AUTOSAR XML (schema 4-2-2)
package /STELLANTIS/EPT/ASWCs
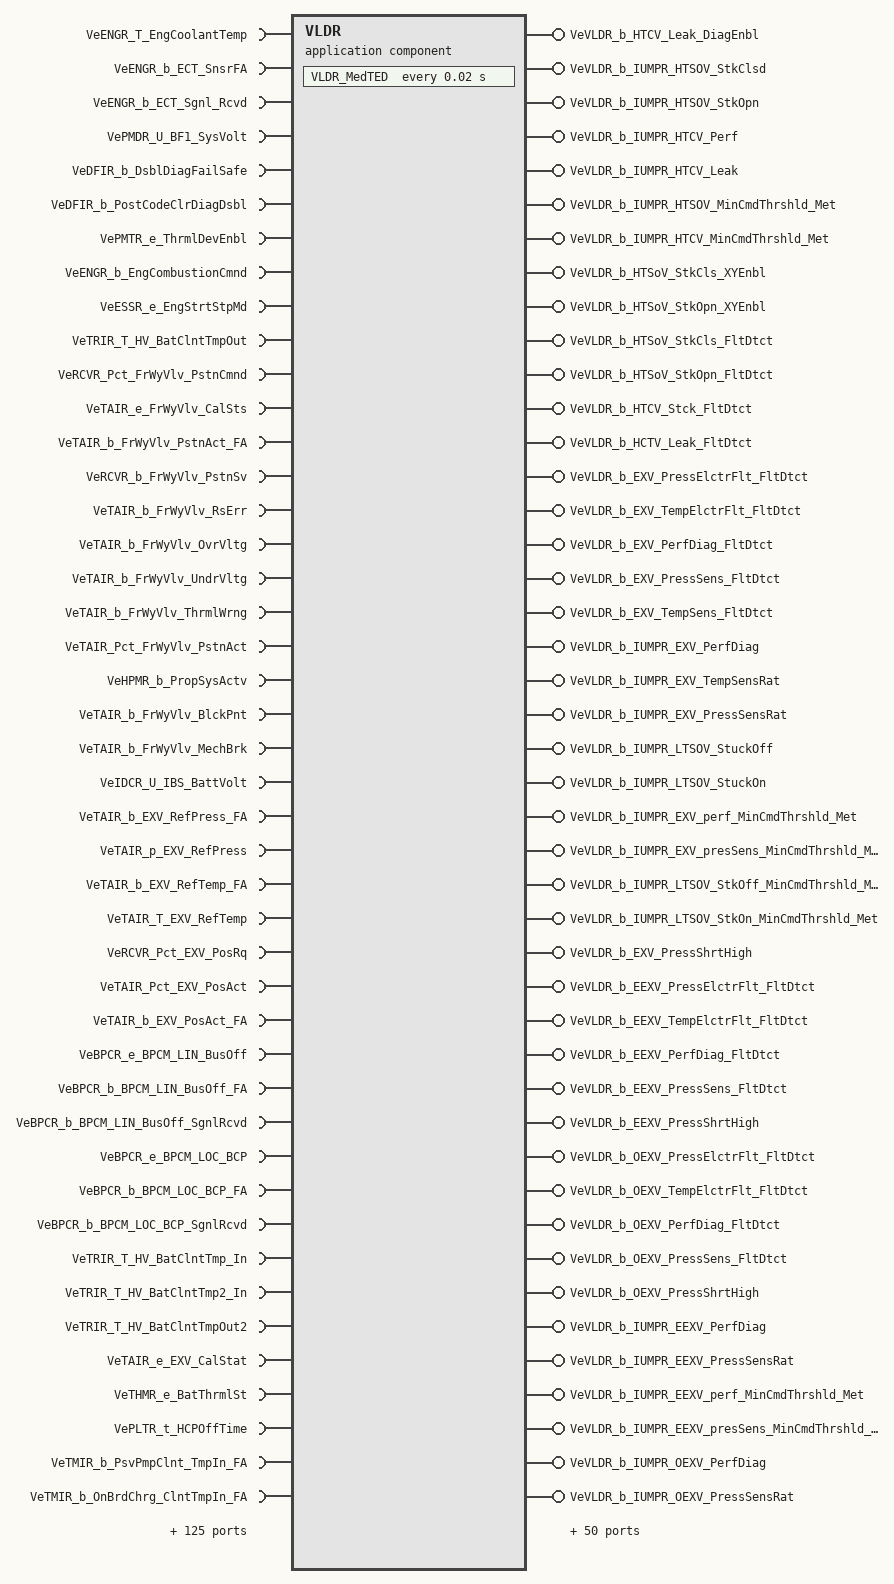
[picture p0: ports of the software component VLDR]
  application sw component type VLDR
    145 x require port:
      VeENGR_T_EngCoolantTemp: variation-point={short-label=vpVeENGR_T_EngCoolantTemp, sw-syscond=1}, nonqueued-receiver-com-spec{data-element=Value, init-value=0}, required-interface=VeENGR_T_EngCoolantTemp
      VeENGR_b_ECT_SnsrFA: variation-point={short-label=vpVeENGR_b_ECT_SnsrFA, sw-syscond=1}, nonqueued-receiver-com-spec{data-element=Value, init-value=0}, required-interface=VeENGR_b_ECT_SnsrFA
      VeENGR_b_ECT_Sgnl_Rcvd: variation-point={short-label=vpVeENGR_b_ECT_Sgnl_Rcvd, sw-syscond=1}, nonqueued-receiver-com-spec{data-element=Value, init-value=0}, required-interface=VeENGR_b_ECT_Sgnl_Rcvd
      VePMDR_U_BF1_SysVolt: variation-point={short-label=vpVePMDR_U_BF1_SysVolt, sw-syscond=1}, nonqueued-receiver-com-spec{data-element=Value, init-value=0}, required-interface=VePMDR_U_BF1_SysVolt
      VeDFIR_b_DsblDiagFailSafe: variation-point={short-label=vpVeDFIR_b_DsblDiagFailSafe, sw-syscond=1}, nonqueued-receiver-com-spec{data-element=Value, init-value=0}, required-interface=VeDFIR_b_DsblDiagFailSafe
      VeDFIR_b_PostCodeClrDiagDsbl: variation-point={short-label=vpVeDFIR_b_PostCodeClrDiagDsbl, sw-syscond=1}, nonqueued-receiver-com-spec{data-element=Value, init-value=0}, required-interface=VeDFIR_b_PostCodeClrDiagDsbl
      VePMTR_e_ThrmlDevEnbl: variation-point={short-label=vpVePMTR_e_ThrmlDevEnbl, sw-syscond=1}, nonqueued-receiver-com-spec{data-element=Value, init-value=CePMTR_e_DISBL_All_Thrml}, required-interface=VePMTR_e_ThrmlDevEnbl
      VeENGR_b_EngCombustionCmnd: variation-point={short-label=vpVeENGR_b_EngCombustionCmnd, sw-syscond=1}, nonqueued-receiver-com-spec{data-element=Value, init-value=0}, required-interface=VeENGR_b_EngCombustionCmnd
      VeESSR_e_EngStrtStpMd: variation-point={short-label=vpVeESSR_e_EngStrtStpMd, sw-syscond=1}, nonqueued-receiver-com-spec{data-element=Value, init-value=CeESSR_e_Stop}, required-interface=VeESSR_e_EngStrtStpMd
      VeTRIR_T_HV_BatClntTmpOut: variation-point={short-label=vpVeTRIR_T_HV_BatClntTmpOut, sw-syscond=1}, nonqueued-receiver-com-spec{data-element=Value, init-value=0}, required-interface=VeTRIR_T_HV_BatClntTmpOut
      VeRCVR_Pct_FrWyVlv_PstnCmnd: variation-point={short-label=vpVeRCVR_Pct_FrWyVlv_PstnCmnd, sw-syscond=1}, nonqueued-receiver-com-spec{data-element=Value, init-value=0}, required-interface=VeRCVR_Pct_FrWyVlv_PstnCmnd
      VeTAIR_e_FrWyVlv_CalSts: variation-point={short-label=vpVeTAIR_e_FrWyVlv_CalSts, sw-syscond=1}, nonqueued-receiver-com-spec{data-element=Value, init-value=CeTAIR_e_CPV_Calibration_Complete}, required-interface=VeTAIR_e_FrWyVlv_CalSts
      VeTAIR_b_FrWyVlv_PstnAct_FA: variation-point={short-label=vpVeTAIR_b_FrWyVlv_PstnAct_FA, sw-syscond=1}, nonqueued-receiver-com-spec{data-element=Value, init-value=0}, required-interface=VeTAIR_b_FrWyVlv_PstnAct_FA
      VeRCVR_b_FrWyVlv_PstnSv: variation-point={short-label=vpVeRCVR_b_FrWyVlv_PstnSv, sw-syscond=1}, nonqueued-receiver-com-spec{data-element=Value, init-value=0}, required-interface=VeRCVR_b_FrWyVlv_PstnSv
      VeTAIR_b_FrWyVlv_RsErr: variation-point={short-label=vpVeTAIR_b_FrWyVlv_RsErr, sw-syscond=1}, nonqueued-receiver-com-spec{data-element=Value, init-value=0}, required-interface=VeTAIR_b_FrWyVlv_RsErr
      VeTAIR_b_FrWyVlv_OvrVltg: variation-point={short-label=vpVeTAIR_b_FrWyVlv_OvrVltg, sw-syscond=1}, nonqueued-receiver-com-spec{data-element=Value, init-value=0}, required-interface=VeTAIR_b_FrWyVlv_OvrVltg
      VeTAIR_b_FrWyVlv_UndrVltg: variation-point={short-label=vpVeTAIR_b_FrWyVlv_UndrVltg, sw-syscond=1}, nonqueued-receiver-com-spec{data-element=Value, init-value=0}, required-interface=VeTAIR_b_FrWyVlv_UndrVltg
      VeTAIR_b_FrWyVlv_ThrmlWrng: variation-point={short-label=vpVeTAIR_b_FrWyVlv_ThrmlWrng, sw-syscond=1}, nonqueued-receiver-com-spec{data-element=Value, init-value=0}, required-interface=VeTAIR_b_FrWyVlv_ThrmlWrng
      VeTAIR_Pct_FrWyVlv_PstnAct: variation-point={short-label=vpVeTAIR_Pct_FrWyVlv_PstnAct, sw-syscond=1}, nonqueued-receiver-com-spec{data-element=Value, init-value=0}, required-interface=VeTAIR_Pct_FrWyVlv_PstnAct
      VeHPMR_b_PropSysActv: variation-point={short-label=vpVeHPMR_b_PropSysActv, sw-syscond=1}, nonqueued-receiver-com-spec{data-element=Value, init-value=0}, required-interface=VeHPMR_b_PropSysActv
      VeTAIR_b_FrWyVlv_BlckPnt: variation-point={short-label=vpVeTAIR_b_FrWyVlv_BlckPnt, sw-syscond=1}, nonqueued-receiver-com-spec{data-element=Value, init-value=0}, required-interface=VeTAIR_b_FrWyVlv_BlckPnt
      VeTAIR_b_FrWyVlv_MechBrk: variation-point={short-label=vpVeTAIR_b_FrWyVlv_MechBrk, sw-syscond=1}, nonqueued-receiver-com-spec{data-element=Value, init-value=0}, required-interface=VeTAIR_b_FrWyVlv_MechBrk
      VeIDCR_U_IBS_BattVolt: variation-point={short-label=vpVeIDCR_U_IBS_BattVolt, sw-syscond=1}, nonqueued-receiver-com-spec{data-element=Value, init-value=0}, required-interface=VeIDCR_U_IBS_BattVolt
      VeTAIR_b_EXV_RefPress_FA: variation-point={short-label=vpVeTAIR_b_EXV_RefPress_FA, sw-syscond=1}, nonqueued-receiver-com-spec{data-element=Value, init-value=0}, required-interface=VeTAIR_b_EXV_RefPress_FA
      VeTAIR_p_EXV_RefPress: variation-point={short-label=vpVeTAIR_p_EXV_RefPress, sw-syscond=1}, nonqueued-receiver-com-spec{data-element=Value, init-value=0}, required-interface=VeTAIR_p_EXV_RefPress
      VeTAIR_b_EXV_RefTemp_FA: variation-point={short-label=vpVeTAIR_b_EXV_RefTemp_FA, sw-syscond=1}, nonqueued-receiver-com-spec{data-element=Value, init-value=0}, required-interface=VeTAIR_b_EXV_RefTemp_FA
      VeTAIR_T_EXV_RefTemp: variation-point={short-label=vpVeTAIR_T_EXV_RefTemp, sw-syscond=1}, nonqueued-receiver-com-spec{data-element=Value, init-value=0}, required-interface=VeTAIR_T_EXV_RefTemp
      VeRCVR_Pct_EXV_PosRq: variation-point={short-label=vpVeRCVR_Pct_EXV_PosRq, sw-syscond=1}, nonqueued-receiver-com-spec{data-element=Value, init-value=0}, required-interface=VeRCVR_Pct_EXV_PosRq
      VeTAIR_Pct_EXV_PosAct: variation-point={short-label=vpVeTAIR_Pct_EXV_PosAct, sw-syscond=1}, nonqueued-receiver-com-spec{data-element=Value, init-value=0}, required-interface=VeTAIR_Pct_EXV_PosAct
      VeTAIR_b_EXV_PosAct_FA: variation-point={short-label=vpVeTAIR_b_EXV_PosAct_FA, sw-syscond=1}, nonqueued-receiver-com-spec{data-element=Value, init-value=0}, required-interface=VeTAIR_b_EXV_PosAct_FA
      VeBPCR_e_BPCM_LIN_BusOff: variation-point={short-label=vpVeBPCR_e_BPCM_LIN_BusOff, sw-syscond=1}, nonqueued-receiver-com-spec{data-element=Value, init-value=CeBPCR_e_LIN_BusOff_Disabled}, required-interface=VeBPCR_e_BPCM_LIN_BusOff
      VeBPCR_b_BPCM_LIN_BusOff_FA: variation-point={short-label=vpVeBPCR_b_BPCM_LIN_BusOff_FA, sw-syscond=1}, nonqueued-receiver-com-spec{data-element=Value, init-value=0}, required-interface=VeBPCR_b_BPCM_LIN_BusOff_FA
      VeBPCR_b_BPCM_LIN_BusOff_SgnlRcvd: variation-point={short-label=vpVeBPCR_b_BPCM_LIN_BusOff_SgnlRcvd, sw-syscond=1}, nonqueued-receiver-com-spec{data-element=Value, init-value=0}, required-interface=VeBPCR_b_BPCM_LIN_BusOff_SgnlRcvd
      VeBPCR_e_BPCM_LOC_BCP: variation-point={short-label=vpVeBPCR_e_BPCM_LOC_BCP, sw-syscond=1}, nonqueued-receiver-com-spec{data-element=Value, init-value=CeBPCR_e_LOC_BCP_False}, required-interface=VeBPCR_e_BPCM_LOC_BCP
      VeBPCR_b_BPCM_LOC_BCP_FA: variation-point={short-label=vpVeBPCR_b_BPCM_LOC_BCP_FA, sw-syscond=1}, nonqueued-receiver-com-spec{data-element=Value, init-value=0}, required-interface=VeBPCR_b_BPCM_LOC_BCP_FA
      VeBPCR_b_BPCM_LOC_BCP_SgnlRcvd: variation-point={short-label=vpVeBPCR_b_BPCM_LOC_BCP_SgnlRcvd, sw-syscond=1}, nonqueued-receiver-com-spec{data-element=Value, init-value=0}, required-interface=VeBPCR_b_BPCM_LOC_BCP_SgnlRcvd
      VeTRIR_T_HV_BatClntTmp_In: variation-point={short-label=vpVeTRIR_T_HV_BatClntTmp_In, sw-syscond=1}, nonqueued-receiver-com-spec{data-element=Value, init-value=0}, required-interface=VeTRIR_T_HV_BatClntTmp_In
      VeTRIR_T_HV_BatClntTmp2_In: variation-point={short-label=vpVeTRIR_T_HV_BatClntTmp2_In, sw-syscond=1}, nonqueued-receiver-com-spec{data-element=Value, init-value=0}, required-interface=VeTRIR_T_HV_BatClntTmp2_In
      VeTRIR_T_HV_BatClntTmpOut2: variation-point={short-label=vpVeTRIR_T_HV_BatClntTmpOut2, sw-syscond=1}, nonqueued-receiver-com-spec{data-element=Value, init-value=0}, required-interface=VeTRIR_T_HV_BatClntTmpOut2
      VeTAIR_e_EXV_CalStat: variation-point={short-label=vpVeTAIR_e_EXV_CalStat, sw-syscond=1}, nonqueued-receiver-com-spec{data-element=Value, init-value=CeTAIR_e_EXV_Calibration_Complete}, required-interface=VeTAIR_e_EXV_CalStat
      VeTHMR_e_BatThrmlSt: variation-point={short-label=vpVeTHMR_e_BatThrmlSt, sw-syscond=1}, nonqueued-receiver-com-spec{data-element=Value, init-value=CeTHMR_e_NoConditioning}, required-interface=VeTHMR_e_BatThrmlSt
      VePLTR_t_HCPOffTime: variation-point={short-label=vpVePLTR_t_HCPOffTime, sw-syscond=1}, nonqueued-receiver-com-spec{data-element=Value, init-value=0}, required-interface=VePLTR_t_HCPOffTime
      VeTMIR_b_PsvPmpClnt_TmpIn_FA: variation-point={short-label=vpVeTMIR_b_PsvPmpClnt_TmpIn_FA, sw-syscond=1}, nonqueued-receiver-com-spec{data-element=Value, init-value=0}, required-interface=VeTMIR_b_PsvPmpClnt_TmpIn_FA
      VeTMIR_b_OnBrdChrg_ClntTmpIn_FA: variation-point={short-label=vpVeTMIR_b_OnBrdChrg_ClntTmpIn_FA, sw-syscond=1}, nonqueued-receiver-com-spec{data-element=Value, init-value=0}, required-interface=VeTMIR_b_OnBrdChrg_ClntTmpIn_FA
      VeRCVR_Pct_LTR_Vlv_PstnCmnd: variation-point={short-label=vpVeRCVR_Pct_LTR_Vlv_PstnCmnd, sw-syscond=1}, nonqueued-receiver-com-spec{data-element=Value, init-value=0}, required-interface=VeRCVR_Pct_LTR_Vlv_PstnCmnd
      VeTAIR_Pct_LTR_BypsVlv_ActlPstn: variation-point={short-label=vpVeTAIR_Pct_LTR_BypsVlv_ActlPstn, sw-syscond=1}, nonqueued-receiver-com-spec{data-element=Value, init-value=0}, required-interface=VeTAIR_Pct_LTR_BypsVlv_ActlPstn
      VeTAIR_b_LTR_BypsVlv_ActlPstn_FA: variation-point={short-label=vpVeTAIR_b_LTR_BypsVlv_ActlPstn_FA, sw-syscond=1}, nonqueued-receiver-com-spec{data-element=Value, init-value=0}, required-interface=VeTAIR_b_LTR_BypsVlv_ActlPstn_FA
      VeRCVR_Pct_HTL_Vlv_PstnCmnd: variation-point={short-label=vpVeRCVR_Pct_HTL_Vlv_PstnCmnd, sw-syscond=1}, nonqueued-receiver-com-spec{data-element=Value, init-value=0}, required-interface=VeRCVR_Pct_HTL_Vlv_PstnCmnd
      VeTAIR_Pct_HTL_BypsVlv_ActlPstn: variation-point={short-label=vpVeTAIR_Pct_HTL_BypsVlv_ActlPstn, sw-syscond=1}, nonqueued-receiver-com-spec{data-element=Value, init-value=0}, required-interface=VeTAIR_Pct_HTL_BypsVlv_ActlPstn
      VeTAIR_b_HTL_BypsVlv_ActlPstn_FA: variation-point={short-label=vpVeTAIR_b_HTL_BypsVlv_ActlPstn_FA, sw-syscond=1}, nonqueued-receiver-com-spec{data-element=Value, init-value=0}, required-interface=VeTAIR_b_HTL_BypsVlv_ActlPstn_FA
      VeDFIR_b_IsDiagGlobalConditionsValid: variation-point={short-label=vpVeDFIR_b_IsDiagGlobalConditionsValid, sw-syscond=1}, nonqueued-receiver-com-spec{data-element=Value, init-value=0}, required-interface=VeDFIR_b_IsDiagGlobalConditionsValid
      VeTAIR_n_CompSpdFdb: variation-point={short-label=vpVeTAIR_n_CompSpdFdb, sw-syscond=1}, nonqueued-receiver-com-spec{data-element=Value, init-value=0}, required-interface=VeTAIR_n_CompSpdFdb
      VeTMIR_b_MainRly_CmdReq: variation-point={short-label=vpVeTMIR_b_MainRly_CmdReq, sw-syscond=1}, nonqueued-receiver-com-spec{data-element=Value, init-value=0}, required-interface=VeTMIR_b_MainRly_CmdReq
      VeTAIR_p_OEXV_RefPress: variation-point={short-label=vpVeTAIR_p_OEXV_RefPress, sw-syscond=1}, nonqueued-receiver-com-spec{data-element=Value, init-value=0}, required-interface=VeTAIR_p_OEXV_RefPress
      VeTAIR_b_OEXV_RefPress_FA: variation-point={short-label=vpVeTAIR_b_OEXV_RefPress_FA, sw-syscond=1}, nonqueued-receiver-com-spec{data-element=Value, init-value=0}, required-interface=VeTAIR_b_OEXV_RefPress_FA
      VeTAIR_T_OEXV_RefTemp: variation-point={short-label=vpVeTAIR_T_OEXV_RefTemp, sw-syscond=1}, nonqueued-receiver-com-spec{data-element=Value, init-value=0}, required-interface=VeTAIR_T_OEXV_RefTemp
      VeRCVR_Pct_OEXV_Cmd: variation-point={short-label=vpVeRCVR_Pct_OEXV_Cmd, sw-syscond=1}, nonqueued-receiver-com-spec{data-element=Value, init-value=0}, required-interface=VeRCVR_Pct_OEXV_Cmd
      VeTAIR_Pct_OEXV_PosAct: variation-point={short-label=vpVeTAIR_Pct_OEXV_PosAct, sw-syscond=1}, nonqueued-receiver-com-spec{data-element=Value, init-value=0}, required-interface=VeTAIR_Pct_OEXV_PosAct
      VeTAIR_b_OEXV_PosAct_FA: variation-point={short-label=vpVeTAIR_b_OEXV_PosAct_FA, sw-syscond=1}, nonqueued-receiver-com-spec{data-element=Value, init-value=0}, required-interface=VeTAIR_b_OEXV_PosAct_FA
      VeTAIR_e_OEXV_CalStat: variation-point={short-label=vpVeTAIR_e_OEXV_CalStat, sw-syscond=1}, nonqueued-receiver-com-spec{data-element=Value, init-value=CeTAIR_e_EXV_Calibration_Complete}, required-interface=VeTAIR_e_OEXV_CalStat
      VeTAIR_e_CompStat: variation-point={short-label=vpVeTAIR_e_CompStat, sw-syscond=1}, nonqueued-receiver-com-spec{data-element=Value, init-value=CeTAIR_e_NormalOp}, required-interface=VeTAIR_e_CompStat
      VeTAIR_b_WinshldDfrst: variation-point={short-label=vpVeTAIR_b_WinshldDfrst, sw-syscond=1}, nonqueued-receiver-com-spec{data-element=Value, init-value=0}, required-interface=VeTAIR_b_WinshldDfrst
      VeTAIR_p_EEXV_RefPress: variation-point={short-label=vpVeTAIR_p_EEXV_RefPress, sw-syscond=1}, nonqueued-receiver-com-spec{data-element=Value, init-value=0}, required-interface=VeTAIR_p_EEXV_RefPress
      VeTAIR_b_EEXV_RefPress_FA: variation-point={short-label=vpVeTAIR_b_EEXV_RefPress_FA, sw-syscond=1}, nonqueued-receiver-com-spec{data-element=Value, init-value=0}, required-interface=VeTAIR_b_EEXV_RefPress_FA
      VeTAIR_T_EEXV_RefTemp: variation-point={short-label=vpVeTAIR_T_EEXV_RefTemp, sw-syscond=1}, nonqueued-receiver-com-spec{data-element=Value, init-value=0}, required-interface=VeTAIR_T_EEXV_RefTemp
      VeRCVR_Pct_EEXV_Cmd: variation-point={short-label=vpVeRCVR_Pct_EEXV_Cmd, sw-syscond=1}, nonqueued-receiver-com-spec{data-element=Value, init-value=0}, required-interface=VeRCVR_Pct_EEXV_Cmd
      VeTAIR_Pct_EEXV_PosAct: variation-point={short-label=vpVeTAIR_Pct_EEXV_PosAct, sw-syscond=1}, nonqueued-receiver-com-spec{data-element=Value, init-value=0}, required-interface=VeTAIR_Pct_EEXV_PosAct
      VeTAIR_b_EEXV_PosAct_FA: variation-point={short-label=vpVeTAIR_b_EEXV_PosAct_FA, sw-syscond=1}, nonqueued-receiver-com-spec{data-element=Value, init-value=0}, required-interface=VeTAIR_b_EEXV_PosAct_FA
      VeTAIR_e_EEXV_CalStat: variation-point={short-label=vpVeTAIR_e_EEXV_CalStat, sw-syscond=1}, nonqueued-receiver-com-spec{data-element=Value, init-value=CeTAIR_e_EXV_Calibration_Complete}, required-interface=VeTAIR_e_EEXV_CalStat
      VeDMAB_y_StatusByte_LIN1_BusOff: nonqueued-receiver-com-spec{data-element=Value, init-value=0}, required-interface=VeDMAB_y_StatusByte_LIN1_BusOff
      VeDMAB_y_StatusByte_LIN2_BusOff: nonqueued-receiver-com-spec{data-element=Value, init-value=0}, required-interface=VeDMAB_y_StatusByte_LIN2_BusOff
      VeDMAB_y_StatusByte_LosCommHybPSCCtrlValA: nonqueued-receiver-com-spec{data-element=Value, init-value=0}, required-interface=VeDMAB_y_StatusByte_LosCommHybPSCCtrlValA
      VeDMAB_y_StatusByte_ThrmlRlyCtrlCkt: nonqueued-receiver-com-spec{data-element=Value, init-value=0}, required-interface=VeDMAB_y_StatusByte_ThrmlRlyCtrlCkt
      VeDMAB_y_StatusByte_LostCommACRefrigExpVlvActC: nonqueued-receiver-com-spec{data-element=Value, init-value=0}, required-interface=VeDMAB_y_StatusByte_LostCommACRefrigExpVlvActC
      VeDMAB_y_StatusByte_AC_RefrigPresSnsrCCktPerf: nonqueued-receiver-com-spec{data-element=Value, init-value=0}, required-interface=VeDMAB_y_StatusByte_AC_RefrigPresSnsrCCktPerf
      VeDMAB_y_StatusByte_AC_RefrigExpVlvAct_C_CntrlCktPerf: nonqueued-receiver-com-spec{data-element=Value, init-value=0}, required-interface=VeDMAB_y_StatusByte_AC_RefrigExpVlvAct_C_CntrlCktPerf
      VeDMAB_y_StatusByte_AC_RefrigPresSnsrAHi: nonqueued-receiver-com-spec{data-element=Value, init-value=0}, required-interface=VeDMAB_y_StatusByte_AC_RefrigPresSnsrAHi
      VeDMAB_y_StatusByte_AC_RefrigPresSnsrALo: nonqueued-receiver-com-spec{data-element=Value, init-value=0}, required-interface=VeDMAB_y_StatusByte_AC_RefrigPresSnsrALo
      VeDMAB_y_StatusByte_AC_RefrigPresSnsrAPerf: nonqueued-receiver-com-spec{data-element=Value, init-value=0}, required-interface=VeDMAB_y_StatusByte_AC_RefrigPresSnsrAPerf
      VeDMAB_y_StatusByte_AC_RefrigPresSnsrCCkt: nonqueued-receiver-com-spec{data-element=Value, init-value=0}, required-interface=VeDMAB_y_StatusByte_AC_RefrigPresSnsrCCkt
      VeDMAB_y_StatusByte_AC_RefrigTempSnsrCCkt: nonqueued-receiver-com-spec{data-element=Value, init-value=0}, required-interface=VeDMAB_y_StatusByte_AC_RefrigTempSnsrCCkt
      VeDMAB_y_StatusByte_AC_RefrigTempSnsrCPerf: nonqueued-receiver-com-spec{data-element=Value, init-value=0}, required-interface=VeDMAB_y_StatusByte_AC_RefrigTempSnsrCPerf
      VeDMAB_y_StatusByte_EACPerf: nonqueued-receiver-com-spec{data-element=Value, init-value=0}, required-interface=VeDMAB_y_StatusByte_EACPerf
      VeDMAB_y_StatusByte_LostCommEAC: nonqueued-receiver-com-spec{data-element=Value, init-value=0}, required-interface=VeDMAB_y_StatusByte_LostCommEAC
      VeDMAB_y_StatusByte_CoolantVlvA_CktHi: nonqueued-receiver-com-spec{data-element=Value, init-value=0}, required-interface=VeDMAB_y_StatusByte_CoolantVlvA_CktHi
      VeDMAB_y_StatusByte_CoolantVlvA_CktLo: nonqueued-receiver-com-spec{data-element=Value, init-value=0}, required-interface=VeDMAB_y_StatusByte_CoolantVlvA_CktLo
      VeDMAB_y_StatusByte_CoolantVlvA_Ckt: nonqueued-receiver-com-spec{data-element=Value, init-value=0}, required-interface=VeDMAB_y_StatusByte_CoolantVlvA_Ckt
      VeDMAB_y_StatusByte_BattCoolPmpATempSnsrPerf: nonqueued-receiver-com-spec{data-element=Value, init-value=0}, required-interface=VeDMAB_y_StatusByte_BattCoolPmpATempSnsrPerf
      VeDMAB_y_StatusByte_CoolOutTempSnsCkt: nonqueued-receiver-com-spec{data-element=Value, init-value=0}, required-interface=VeDMAB_y_StatusByte_CoolOutTempSnsCkt
      VeDMAB_y_StatusByte_HB_CT_SnsrPerf: nonqueued-receiver-com-spec{data-element=Value, init-value=0}, required-interface=VeDMAB_y_StatusByte_HB_CT_SnsrPerf
      VeDMAB_y_StatusByte_CoolantVlvA_FdbkCktHi: nonqueued-receiver-com-spec{data-element=Value, init-value=0}, required-interface=VeDMAB_y_StatusByte_CoolantVlvA_FdbkCktHi
      VeDMAB_y_StatusByte_CoolantVlvA_FdbkCktLo: nonqueued-receiver-com-spec{data-element=Value, init-value=0}, required-interface=VeDMAB_y_StatusByte_CoolantVlvA_FdbkCktLo
      VeDMAB_y_StatusByte_LIN3_BusOff: nonqueued-receiver-com-spec{data-element=Value, init-value=0}, required-interface=VeDMAB_y_StatusByte_LIN3_BusOff
      VeDMAB_y_StatusByte_LostCommHB_PSCCooCtrlVlvC: nonqueued-receiver-com-spec{data-element=Value, init-value=0}, required-interface=VeDMAB_y_StatusByte_LostCommHB_PSCCooCtrlVlvC
      VeDMAB_y_StatusByte_CoolantVlvB_CktHi: nonqueued-receiver-com-spec{data-element=Value, init-value=0}, required-interface=VeDMAB_y_StatusByte_CoolantVlvB_CktHi
      VeDMAB_y_StatusByte_CoolantVlvB_CktLo: nonqueued-receiver-com-spec{data-element=Value, init-value=0}, required-interface=VeDMAB_y_StatusByte_CoolantVlvB_CktLo
      VeDMAB_y_StatusByte_CoolantVlvB_Ckt: nonqueued-receiver-com-spec{data-element=Value, init-value=0}, required-interface=VeDMAB_y_StatusByte_CoolantVlvB_Ckt
      VeDMAB_y_StatusByte_LostCommCoolHtrA: nonqueued-receiver-com-spec{data-element=Value, init-value=0}, required-interface=VeDMAB_y_StatusByte_LostCommCoolHtrA
      VeDMAB_y_StatusByte_CoolantVlvB_StkClsd: nonqueued-receiver-com-spec{data-element=Value, init-value=0}, required-interface=VeDMAB_y_StatusByte_CoolantVlvB_StkClsd
      VeDMAB_y_StatusByte_CoolantVlvB_StkOpn: nonqueued-receiver-com-spec{data-element=Value, init-value=0}, required-interface=VeDMAB_y_StatusByte_CoolantVlvB_StkOpn
      VeDMAB_y_StatusByte_CT_SnsrCktHi: nonqueued-receiver-com-spec{data-element=Value, init-value=0}, required-interface=VeDMAB_y_StatusByte_CT_SnsrCktHi
      VeDMAB_y_StatusByte_CT_SnsrCktLo: nonqueued-receiver-com-spec{data-element=Value, init-value=0}, required-interface=VeDMAB_y_StatusByte_CT_SnsrCktLo
      VeDMAB_y_StatusByte_CT_SnsrPerf: nonqueued-receiver-com-spec{data-element=Value, init-value=0}, required-interface=VeDMAB_y_StatusByte_CT_SnsrPerf
      VeDMAB_y_StatusByte_HybEvBatPacCoolCtrlVlvBStkOn: nonqueued-receiver-com-spec{data-element=Value, init-value=0}, required-interface=VeDMAB_y_StatusByte_HybEvBatPacCoolCtrlVlvBStkOn
      VeDMAB_y_StatusByte_LosCommBECM_A: nonqueued-receiver-com-spec{data-element=Value, init-value=0}, required-interface=VeDMAB_y_StatusByte_LosCommBECM_A
      VeDMAB_y_StatusByte_MtrElect_CT_SnsrCktHi: nonqueued-receiver-com-spec{data-element=Value, init-value=0}, required-interface=VeDMAB_y_StatusByte_MtrElect_CT_SnsrCktHi
      VeDMAB_y_StatusByte_MtrElect_CT_SnsrCktLo: nonqueued-receiver-com-spec{data-element=Value, init-value=0}, required-interface=VeDMAB_y_StatusByte_MtrElect_CT_SnsrCktLo
      VeDMAB_y_StatusByte_MtrElect_CT_SnsrPerf: nonqueued-receiver-com-spec{data-element=Value, init-value=0}, required-interface=VeDMAB_y_StatusByte_MtrElect_CT_SnsrPerf
      VeDMAB_y_StatusByte_HybEvBatPacCoolCtrlVlvBPerfStkOff: nonqueued-receiver-com-spec{data-element=Value, init-value=0}, required-interface=VeDMAB_y_StatusByte_HybEvBatPacCoolCtrlVlvBPerfStkOff
      VeDMAB_y_StatusByte_LostCommHB_PSCCooCtrlVlvB: nonqueued-receiver-com-spec{data-element=Value, init-value=0}, required-interface=VeDMAB_y_StatusByte_LostCommHB_PSCCooCtrlVlvB
      VeDMAB_y_StatusByte_CommBusOff: nonqueued-receiver-com-spec{data-element=Value, init-value=0}, required-interface=VeDMAB_y_StatusByte_CommBusOff
      VeDMAB_y_StatusByte_HybEvBatPacCoolCtrlVlv2CtrlCktHi: nonqueued-receiver-com-spec{data-element=Value, init-value=0}, required-interface=VeDMAB_y_StatusByte_HybEvBatPacCoolCtrlVlv2CtrlCktHi
      VeDMAB_y_StatusByte_HybEvBatPacCoolCtrlVlv2CtrlCktLo: nonqueued-receiver-com-spec{data-element=Value, init-value=0}, required-interface=VeDMAB_y_StatusByte_HybEvBatPacCoolCtrlVlv2CtrlCktLo
      VeDMAB_y_StatusByte_MtrElect_CoolPumBCtrlPerf: nonqueued-receiver-com-spec{data-element=Value, init-value=0}, required-interface=VeDMAB_y_StatusByte_MtrElect_CoolPumBCtrlPerf
      VeDMAB_y_StatusByte_LostCommACRefrigExpVlvActD: nonqueued-receiver-com-spec{data-element=Value, init-value=0}, required-interface=VeDMAB_y_StatusByte_LostCommACRefrigExpVlvActD
      VeDMAB_y_StatusByte_AC_RefrigPresSnsrDCktPerf: nonqueued-receiver-com-spec{data-element=Value, init-value=0}, required-interface=VeDMAB_y_StatusByte_AC_RefrigPresSnsrDCktPerf
      VeDMAB_y_StatusByte_AC_RefrigExpVlvActD_CntrlCktPerf: nonqueued-receiver-com-spec{data-element=Value, init-value=0}, required-interface=VeDMAB_y_StatusByte_AC_RefrigExpVlvActD_CntrlCktPerf
      VeDMAB_y_StatusByte_AC_RefrigPresSnsrDCkt: nonqueued-receiver-com-spec{data-element=Value, init-value=0}, required-interface=VeDMAB_y_StatusByte_AC_RefrigPresSnsrDCkt
      VeDMAB_y_StatusByte_AC_RefrigTempSnsr4CktPerf: nonqueued-receiver-com-spec{data-element=Value, init-value=0}, required-interface=VeDMAB_y_StatusByte_AC_RefrigTempSnsr4CktPerf
      VeDMAB_y_StatusByte_AC_RefrigTempSnsrDCkt: nonqueued-receiver-com-spec{data-element=Value, init-value=0}, required-interface=VeDMAB_y_StatusByte_AC_RefrigTempSnsrDCkt
      VeDMAB_y_StatusByte_LostCommACRefrigExpVlvActA: nonqueued-receiver-com-spec{data-element=Value, init-value=0}, required-interface=VeDMAB_y_StatusByte_LostCommACRefrigExpVlvActA
      VeDMAB_y_StatusByte_AC_RefrigTempSnsrBPerf: nonqueued-receiver-com-spec{data-element=Value, init-value=0}, required-interface=VeDMAB_y_StatusByte_AC_RefrigTempSnsrBPerf
      VeDMAB_y_StatusByte_AC_RefrigExpVlvActCtrCktPerf: nonqueued-receiver-com-spec{data-element=Value, init-value=0}, required-interface=VeDMAB_y_StatusByte_AC_RefrigExpVlvActCtrCktPerf
      VeDMAB_y_StatusByte_AC_RefrigTempSnsrACkt: nonqueued-receiver-com-spec{data-element=Value, init-value=0}, required-interface=VeDMAB_y_StatusByte_AC_RefrigTempSnsrACkt
      VeDMAB_y_StatusByte_AC_RefrigTempSnsrAPerf: nonqueued-receiver-com-spec{data-element=Value, init-value=0}, required-interface=VeDMAB_y_StatusByte_AC_RefrigTempSnsrAPerf
      VeDMAB_y_StatusByte_AC_RefrigTempSnsrBCkt: nonqueued-receiver-com-spec{data-element=Value, init-value=0}, required-interface=VeDMAB_y_StatusByte_AC_RefrigTempSnsrBCkt
      VeDMAB_y_StatusByte_BattCoolPmpOveSpd: nonqueued-receiver-com-spec{data-element=Value, init-value=0}, required-interface=VeDMAB_y_StatusByte_BattCoolPmpOveSpd
      VeDMAB_y_StatusByte_BattCoolPmpPerf: nonqueued-receiver-com-spec{data-element=Value, init-value=0}, required-interface=VeDMAB_y_StatusByte_BattCoolPmpPerf
      VeDMAB_y_StatusByte_CommBus_B_Off: nonqueued-receiver-com-spec{data-element=Value, init-value=0}, required-interface=VeDMAB_y_StatusByte_CommBus_B_Off
      VeDMAB_y_StatusByte_InvData_BECM_CANC11: nonqueued-receiver-com-spec{data-element=Value, init-value=0}, required-interface=VeDMAB_y_StatusByte_InvData_BECM_CANC11
      VeDMAB_y_StatusByte_InvData_BECM: nonqueued-receiver-com-spec{data-element=Value, init-value=0}, required-interface=VeDMAB_y_StatusByte_InvData_BECM
      VeDMAB_y_StatusByte_LosCommBECM_A_CANC11: nonqueued-receiver-com-spec{data-element=Value, init-value=0}, required-interface=VeDMAB_y_StatusByte_LosCommBECM_A_CANC11
      VeDMAB_y_StatusByte_HybBattCooTempSnsrCPer: nonqueued-receiver-com-spec{data-element=Value, init-value=0}, required-interface=VeDMAB_y_StatusByte_HybBattCooTempSnsrCPer
      VeDMAB_y_StatusByte_HybBattCooTempSnsrDPer: nonqueued-receiver-com-spec{data-element=Value, init-value=0}, required-interface=VeDMAB_y_StatusByte_HybBattCooTempSnsrDPer
      VeDMAB_y_StatusByte_EngCoolbypsVlvDPerf: nonqueued-receiver-com-spec{data-element=Value, init-value=0}, required-interface=VeDMAB_y_StatusByte_EngCoolbypsVlvDPerf
      VeDMAB_y_StatusByte_LostCommEngCoolbypsVlvD: nonqueued-receiver-com-spec{data-element=Value, init-value=0}, required-interface=VeDMAB_y_StatusByte_LostCommEngCoolbypsVlvD
      VeDMAB_y_StatusByte_HB_PSC_CtrlValACktPerf: nonqueued-receiver-com-spec{data-element=Value, init-value=0}, required-interface=VeDMAB_y_StatusByte_HB_PSC_CtrlValACktPerf
      VeDMAB_y_StatusByte_HB_PSC_CtrlValBCktPerf: nonqueued-receiver-com-spec{data-element=Value, init-value=0}, required-interface=VeDMAB_y_StatusByte_HB_PSC_CtrlValBCktPerf
      VeDMAB_y_StatusByte_HB_PSC_CtrlValCCktPerf: nonqueued-receiver-com-spec{data-element=Value, init-value=0}, required-interface=VeDMAB_y_StatusByte_HB_PSC_CtrlValCCktPerf
      VePLTR_b_HCPOffTimeFA: variation-point={short-label=vpVePLTR_b_HCPOffTimeFA, sw-syscond=1}, nonqueued-receiver-com-spec{data-element=Value, init-value=0}, required-interface=VePLTR_b_HCPOffTimeFA
      VeDMAB_y_StatusByte_HybPropSysCoolCntrlVal_E_Perf: nonqueued-receiver-com-spec{data-element=Value, init-value=0}, required-interface=VeDMAB_y_StatusByte_HybPropSysCoolCntrlVal_E_Perf
      VeTAIR_e_CPV2_CalSts: variation-point={short-label=vpVeTAIR_e_CPV2_CalSts, sw-syscond=1}, nonqueued-receiver-com-spec{data-element=Value, init-value=CeTAIR_e_CPV_Calibration_Complete}, required-interface=VeTAIR_e_CPV2_CalSts
      VeTAIR_Pct_CPV2_PstnAct: variation-point={short-label=vpVeTAIR_Pct_CPV2_PstnAct, sw-syscond=1}, nonqueued-receiver-com-spec{data-element=Value, init-value=0}, required-interface=VeTAIR_Pct_CPV2_PstnAct
      VeRCVR_Pct_HtrCoreBypVlv_PstnCmnd: variation-point={short-label=vpVeRCVR_Pct_HtrCoreBypVlv_PstnCmnd, sw-syscond=1}, nonqueued-receiver-com-spec{data-element=Value, init-value=0}, required-interface=VeRCVR_Pct_HtrCoreBypVlv_PstnCmnd
      VeDMAB_y_StatusByte_LostComm_HybPropSysCoolCntrlVal_E: nonqueued-receiver-com-spec{data-element=Value, init-value=0}, required-interface=VeDMAB_y_StatusByte_LostComm_HybPropSysCoolCntrlVal_E
    70 x provide port:
      VeVLDR_b_HTCV_Leak_DiagEnbl: nonqueued-sender-com-spec{data-element=Value, init-value=0}, provided-interface=VeVLDR_b_HTCV_Leak_DiagEnbl
      VeVLDR_b_IUMPR_HTSOV_StkClsd: nonqueued-sender-com-spec{data-element=Value, init-value=0}, provided-interface=VeVLDR_b_IUMPR_HTSOV_StkClsd
      VeVLDR_b_IUMPR_HTSOV_StkOpn: nonqueued-sender-com-spec{data-element=Value, init-value=0}, provided-interface=VeVLDR_b_IUMPR_HTSOV_StkOpn
      VeVLDR_b_IUMPR_HTCV_Perf: nonqueued-sender-com-spec{data-element=Value, init-value=0}, provided-interface=VeVLDR_b_IUMPR_HTCV_Perf
      VeVLDR_b_IUMPR_HTCV_Leak: nonqueued-sender-com-spec{data-element=Value, init-value=0}, provided-interface=VeVLDR_b_IUMPR_HTCV_Leak
      VeVLDR_b_IUMPR_HTSOV_MinCmdThrshld_Met: nonqueued-sender-com-spec{data-element=Value, init-value=0}, provided-interface=VeVLDR_b_IUMPR_HTSOV_MinCmdThrshld_Met
      VeVLDR_b_IUMPR_HTCV_MinCmdThrshld_Met: nonqueued-sender-com-spec{data-element=Value, init-value=0}, provided-interface=VeVLDR_b_IUMPR_HTCV_MinCmdThrshld_Met
      VeVLDR_b_HTSoV_StkCls_XYEnbl: nonqueued-sender-com-spec{data-element=Value, init-value=0}, provided-interface=VeVLDR_b_HTSoV_StkCls_XYEnbl
      VeVLDR_b_HTSoV_StkOpn_XYEnbl: nonqueued-sender-com-spec{data-element=Value, init-value=0}, provided-interface=VeVLDR_b_HTSoV_StkOpn_XYEnbl
      VeVLDR_b_HTSoV_StkCls_FltDtct: nonqueued-sender-com-spec{data-element=Value, init-value=0}, provided-interface=VeVLDR_b_HTSoV_StkCls_FltDtct
      VeVLDR_b_HTSoV_StkOpn_FltDtct: nonqueued-sender-com-spec{data-element=Value, init-value=0}, provided-interface=VeVLDR_b_HTSoV_StkOpn_FltDtct
      VeVLDR_b_HTCV_Stck_FltDtct: nonqueued-sender-com-spec{data-element=Value, init-value=0}, provided-interface=VeVLDR_b_HTCV_Stck_FltDtct
      VeVLDR_b_HCTV_Leak_FltDtct: nonqueued-sender-com-spec{data-element=Value, init-value=0}, provided-interface=VeVLDR_b_HCTV_Leak_FltDtct
      VeVLDR_b_EXV_PressElctrFlt_FltDtct: nonqueued-sender-com-spec{data-element=Value, init-value=0}, provided-interface=VeVLDR_b_EXV_PressElctrFlt_FltDtct
      VeVLDR_b_EXV_TempElctrFlt_FltDtct: nonqueued-sender-com-spec{data-element=Value, init-value=0}, provided-interface=VeVLDR_b_EXV_TempElctrFlt_FltDtct
      VeVLDR_b_EXV_PerfDiag_FltDtct: nonqueued-sender-com-spec{data-element=Value, init-value=0}, provided-interface=VeVLDR_b_EXV_PerfDiag_FltDtct
      VeVLDR_b_EXV_PressSens_FltDtct: nonqueued-sender-com-spec{data-element=Value, init-value=0}, provided-interface=VeVLDR_b_EXV_PressSens_FltDtct
      VeVLDR_b_EXV_TempSens_FltDtct: nonqueued-sender-com-spec{data-element=Value, init-value=0}, provided-interface=VeVLDR_b_EXV_TempSens_FltDtct
      VeVLDR_b_IUMPR_EXV_PerfDiag: nonqueued-sender-com-spec{data-element=Value, init-value=0}, provided-interface=VeVLDR_b_IUMPR_EXV_PerfDiag
      VeVLDR_b_IUMPR_EXV_TempSensRat: nonqueued-sender-com-spec{data-element=Value, init-value=0}, provided-interface=VeVLDR_b_IUMPR_EXV_TempSensRat
      VeVLDR_b_IUMPR_EXV_PressSensRat: nonqueued-sender-com-spec{data-element=Value, init-value=0}, provided-interface=VeVLDR_b_IUMPR_EXV_PressSensRat
      VeVLDR_b_IUMPR_LTSOV_StuckOff: nonqueued-sender-com-spec{data-element=Value, init-value=0}, provided-interface=VeVLDR_b_IUMPR_LTSOV_StuckOff
      VeVLDR_b_IUMPR_LTSOV_StuckOn: nonqueued-sender-com-spec{data-element=Value, init-value=0}, provided-interface=VeVLDR_b_IUMPR_LTSOV_StuckOn
      VeVLDR_b_IUMPR_EXV_perf_MinCmdThrshld_Met: nonqueued-sender-com-spec{data-element=Value, init-value=0}, provided-interface=VeVLDR_b_IUMPR_EXV_perf_MinCmdThrshld_Met
      VeVLDR_b_IUMPR_EXV_presSens_MinCmdThrshld_Met: nonqueued-sender-com-spec{data-element=Value, init-value=0}, provided-interface=VeVLDR_b_IUMPR_EXV_presSens_MinCmdThrshld_Met
      VeVLDR_b_IUMPR_LTSOV_StkOff_MinCmdThrshld_Met: nonqueued-sender-com-spec{data-element=Value, init-value=0}, provided-interface=VeVLDR_b_IUMPR_LTSOV_StkOff_MinCmdThrshld_Met
      VeVLDR_b_IUMPR_LTSOV_StkOn_MinCmdThrshld_Met: nonqueued-sender-com-spec{data-element=Value, init-value=0}, provided-interface=VeVLDR_b_IUMPR_LTSOV_StkOn_MinCmdThrshld_Met
      VeVLDR_b_EXV_PressShrtHigh: nonqueued-sender-com-spec{data-element=Value, init-value=0}, provided-interface=VeVLDR_b_EXV_PressShrtHigh
      VeVLDR_b_EEXV_PressElctrFlt_FltDtct: nonqueued-sender-com-spec{data-element=Value, init-value=0}, provided-interface=VeVLDR_b_EEXV_PressElctrFlt_FltDtct
      VeVLDR_b_EEXV_TempElctrFlt_FltDtct: nonqueued-sender-com-spec{data-element=Value, init-value=0}, provided-interface=VeVLDR_b_EEXV_TempElctrFlt_FltDtct
      VeVLDR_b_EEXV_PerfDiag_FltDtct: nonqueued-sender-com-spec{data-element=Value, init-value=0}, provided-interface=VeVLDR_b_EEXV_PerfDiag_FltDtct
      VeVLDR_b_EEXV_PressSens_FltDtct: nonqueued-sender-com-spec{data-element=Value, init-value=0}, provided-interface=VeVLDR_b_EEXV_PressSens_FltDtct
      VeVLDR_b_EEXV_PressShrtHigh: nonqueued-sender-com-spec{data-element=Value, init-value=0}, provided-interface=VeVLDR_b_EEXV_PressShrtHigh
      VeVLDR_b_OEXV_PressElctrFlt_FltDtct: nonqueued-sender-com-spec{data-element=Value, init-value=0}, provided-interface=VeVLDR_b_OEXV_PressElctrFlt_FltDtct
      VeVLDR_b_OEXV_TempElctrFlt_FltDtct: nonqueued-sender-com-spec{data-element=Value, init-value=0}, provided-interface=VeVLDR_b_OEXV_TempElctrFlt_FltDtct
      VeVLDR_b_OEXV_PerfDiag_FltDtct: nonqueued-sender-com-spec{data-element=Value, init-value=0}, provided-interface=VeVLDR_b_OEXV_PerfDiag_FltDtct
      VeVLDR_b_OEXV_PressSens_FltDtct: nonqueued-sender-com-spec{data-element=Value, init-value=0}, provided-interface=VeVLDR_b_OEXV_PressSens_FltDtct
      VeVLDR_b_OEXV_PressShrtHigh: nonqueued-sender-com-spec{data-element=Value, init-value=0}, provided-interface=VeVLDR_b_OEXV_PressShrtHigh
      VeVLDR_b_IUMPR_EEXV_PerfDiag: nonqueued-sender-com-spec{data-element=Value, init-value=0}, provided-interface=VeVLDR_b_IUMPR_EEXV_PerfDiag
      VeVLDR_b_IUMPR_EEXV_PressSensRat: nonqueued-sender-com-spec{data-element=Value, init-value=0}, provided-interface=VeVLDR_b_IUMPR_EEXV_PressSensRat
      VeVLDR_b_IUMPR_EEXV_perf_MinCmdThrshld_Met: nonqueued-sender-com-spec{data-element=Value, init-value=0}, provided-interface=VeVLDR_b_IUMPR_EEXV_perf_MinCmdThrshld_Met
      VeVLDR_b_IUMPR_EEXV_presSens_MinCmdThrshld_Met: nonqueued-sender-com-spec{data-element=Value, init-value=0}, provided-interface=VeVLDR_b_IUMPR_EEXV_presSens_MinCmdThrshld_Met
      VeVLDR_b_IUMPR_OEXV_PerfDiag: nonqueued-sender-com-spec{data-element=Value, init-value=0}, provided-interface=VeVLDR_b_IUMPR_OEXV_PerfDiag
      VeVLDR_b_IUMPR_OEXV_PressSensRat: nonqueued-sender-com-spec{data-element=Value, init-value=0}, provided-interface=VeVLDR_b_IUMPR_OEXV_PressSensRat
      VeVLDR_b_IUMPR_OEXV_perf_MinCmdThrshld_Met: nonqueued-sender-com-spec{data-element=Value, init-value=0}, provided-interface=VeVLDR_b_IUMPR_OEXV_perf_MinCmdThrshld_Met
      VeVLDR_b_IUMPR_OEXV_presSens_MinCmdThrshld_Met: nonqueued-sender-com-spec{data-element=Value, init-value=0}, provided-interface=VeVLDR_b_IUMPR_OEXV_presSens_MinCmdThrshld_Met
      VeVLDR_e_FaultSts_HB_PSC_CtrlValACktPerf: nonqueued-sender-com-spec{data-element=Value, init-value=CeDFIB_e_Init}, provided-interface=VeVLDR_e_FaultSts_HB_PSC_CtrlValACktPerf
      VeVLDR_e_FaultSts_AC_RefrigExpVlvAct_C_CntrlCktPerf: nonqueued-sender-com-spec{data-element=Value, init-value=CeDFIB_e_Init}, provided-interface=VeVLDR_e_FaultSts_AC_RefrigExpVlvAct_C_CntrlCktPerf
      VeVLDR_e_FaultSts_AC_RefrigPresSnsrCCkt: nonqueued-sender-com-spec{data-element=Value, init-value=CeDFIB_e_Init}, provided-interface=VeVLDR_e_FaultSts_AC_RefrigPresSnsrCCkt
      VeVLDR_e_FaultSts_AC_RefrigPresSnsrCCktPerf: nonqueued-sender-com-spec{data-element=Value, init-value=CeDFIB_e_Init}, provided-interface=VeVLDR_e_FaultSts_AC_RefrigPresSnsrCCktPerf
      VeVLDR_e_FaultSts_AC_RefrigTempSnsrCCkt: nonqueued-sender-com-spec{data-element=Value, init-value=CeDFIB_e_Init}, provided-interface=VeVLDR_e_FaultSts_AC_RefrigTempSnsrCCkt
      VeVLDR_e_FaultSts_CoolantVlvA_StkOpn: nonqueued-sender-com-spec{data-element=Value, init-value=CeDFIB_e_Init}, provided-interface=VeVLDR_e_FaultSts_CoolantVlvA_StkOpn
      VeVLDR_e_FaultSts_CoolantVlvA_Perf: nonqueued-sender-com-spec{data-element=Value, init-value=CeDFIB_e_Init}, provided-interface=VeVLDR_e_FaultSts_CoolantVlvA_Perf
      VeVLDR_e_FaultSts_HB_PSC_CtrlValCCktPerf: nonqueued-sender-com-spec{data-element=Value, init-value=CeDFIB_e_Init}, provided-interface=VeVLDR_e_FaultSts_HB_PSC_CtrlValCCktPerf
      VeVLDR_e_FaultSts_CoolantVlvB_StkClsd: nonqueued-sender-com-spec{data-element=Value, init-value=CeDFIB_e_Init}, provided-interface=VeVLDR_e_FaultSts_CoolantVlvB_StkClsd
      VeVLDR_e_FaultSts_CoolantVlvB_StkOpn: nonqueued-sender-com-spec{data-element=Value, init-value=CeDFIB_e_Init}, provided-interface=VeVLDR_e_FaultSts_CoolantVlvB_StkOpn
      VeVLDR_e_FaultSts_HB_PSC_CtrlValBCktPerf: nonqueued-sender-com-spec{data-element=Value, init-value=CeDFIB_e_Init}, provided-interface=VeVLDR_e_FaultSts_HB_PSC_CtrlValBCktPerf
      VeVLDR_e_FaultSts_HybEvBatPacCoolCtrlVlvBPerfStkOff: nonqueued-sender-com-spec{data-element=Value, init-value=CeDFIB_e_Init}, provided-interface=VeVLDR_e_FaultSts_HybEvBatPacCoolCtrlVlvBPerfStkOff
      VeVLDR_e_FaultSts_HybEvBatPacCoolCtrlVlvBStkOn: nonqueued-sender-com-spec{data-element=Value, init-value=CeDFIB_e_Init}, provided-interface=VeVLDR_e_FaultSts_HybEvBatPacCoolCtrlVlvBStkOn
      VeVLDR_e_FaultSts_AC_RefrigExpVlvActD_CntrlCktPerf: nonqueued-sender-com-spec{data-element=Value, init-value=CeDFIB_e_Init}, provided-interface=VeVLDR_e_FaultSts_AC_RefrigExpVlvActD_CntrlCktPerf
      VeVLDR_e_FaultSts_AC_RefrigPresSnsrDCkt: nonqueued-sender-com-spec{data-element=Value, init-value=CeDFIB_e_Init}, provided-interface=VeVLDR_e_FaultSts_AC_RefrigPresSnsrDCkt
      VeVLDR_e_FaultSts_AC_RefrigPresSnsrDCktPerf: nonqueued-sender-com-spec{data-element=Value, init-value=CeDFIB_e_Init}, provided-interface=VeVLDR_e_FaultSts_AC_RefrigPresSnsrDCktPerf
      VeVLDR_e_FaultSts_AC_RefrigTempSnsrDCkt: nonqueued-sender-com-spec{data-element=Value, init-value=CeDFIB_e_Init}, provided-interface=VeVLDR_e_FaultSts_AC_RefrigTempSnsrDCkt
      VeVLDR_e_FaultSts_AC_RefrigExpVlvActCtrCktPerf: nonqueued-sender-com-spec{data-element=Value, init-value=CeDFIB_e_Init}, provided-interface=VeVLDR_e_FaultSts_AC_RefrigExpVlvActCtrCktPerf
      VeVLDR_e_FaultSts_AC_RefrigTempSnsrBCkt: nonqueued-sender-com-spec{data-element=Value, init-value=CeDFIB_e_Init}, provided-interface=VeVLDR_e_FaultSts_AC_RefrigTempSnsrBCkt
      VeVLDR_e_FaultSts_AC_RefrigTempSnsrBPerf: nonqueued-sender-com-spec{data-element=Value, init-value=CeDFIB_e_Init}, provided-interface=VeVLDR_e_FaultSts_AC_RefrigTempSnsrBPerf
      VeVLDR_e_FaultSts_AC_RefrigTempSnsrACkt: nonqueued-sender-com-spec{data-element=Value, init-value=CeDFIB_e_Init}, provided-interface=VeVLDR_e_FaultSts_AC_RefrigTempSnsrACkt
      VeVLDR_e_FaultSts_AC_RefrigTempSnsrAPerf: nonqueued-sender-com-spec{data-element=Value, init-value=CeDFIB_e_Init}, provided-interface=VeVLDR_e_FaultSts_AC_RefrigTempSnsrAPerf
      VeVLDR_e_FaultSts_EngCoolbypsVlvDPerf: nonqueued-sender-com-spec{data-element=Value, init-value=CeDFIB_e_Init}, provided-interface=VeVLDR_e_FaultSts_EngCoolbypsVlvDPerf
      VeVLDR_e_FaultSts_HybPropSysCoolCntrlVal_E_Perf: nonqueued-sender-com-spec{data-element=Value, init-value=CeDFIB_e_Init}, provided-interface=VeVLDR_e_FaultSts_HybPropSysCoolCntrlVal_E_Perf
    24 x require port:
      NeVLDR_Cnt_CPV_PerfDiag_MFOP_Rx: nv-require-com-spec{init-value=0, variable=NeVLDR_Cnt_CPV_PerfDiag_MFOP}, required-interface=NeVLDR_Cnt_CPV_PerfDiag_MFOP
      NeVLDR_Cnt_CabVlvOpeng_Err_MFOP_Rx: nv-require-com-spec{init-value=0, variable=NeVLDR_Cnt_CabVlvOpeng_Err_MFOP}, required-interface=NeVLDR_Cnt_CabVlvOpeng_Err_MFOP
      NeVLDR_Cnt_EEXV_PerfDiag_MFOP_Rx: nv-require-com-spec{init-value=0, variable=NeVLDR_Cnt_EEXV_PerfDiag_MFOP}, required-interface=NeVLDR_Cnt_EEXV_PerfDiag_MFOP
      NeVLDR_Cnt_EEXV_PressElctrFlt_MFOP_Rx: nv-require-com-spec{init-value=0, variable=NeVLDR_Cnt_EEXV_PressElctrFlt_MFOP}, required-interface=NeVLDR_Cnt_EEXV_PressElctrFlt_MFOP
      NeVLDR_Cnt_EEXV_PressSens_MFOP_Rx: nv-require-com-spec{init-value=0, variable=NeVLDR_Cnt_EEXV_PressSens_MFOP}, required-interface=NeVLDR_Cnt_EEXV_PressSens_MFOP
      NeVLDR_Cnt_EEXV_TempElctrFlt_MFOP_Rx: nv-require-com-spec{init-value=0, variable=NeVLDR_Cnt_EEXV_TempElctrFlt_MFOP}, required-interface=NeVLDR_Cnt_EEXV_TempElctrFlt_MFOP
      NeVLDR_Cnt_EXV_PerfDiag_MFOP_Rx: nv-require-com-spec{init-value=0, variable=NeVLDR_Cnt_EXV_PerfDiag_MFOP}, required-interface=NeVLDR_Cnt_EXV_PerfDiag_MFOP
      NeVLDR_Cnt_EXV_PressElctrFlt_MFOP_Rx: nv-require-com-spec{init-value=0, variable=NeVLDR_Cnt_EXV_PressElctrFlt_MFOP}, required-interface=NeVLDR_Cnt_EXV_PressElctrFlt_MFOP
      NeVLDR_Cnt_EXV_PressSens_MFOP_Rx: nv-require-com-spec{init-value=0, variable=NeVLDR_Cnt_EXV_PressSens_MFOP}, required-interface=NeVLDR_Cnt_EXV_PressSens_MFOP
      NeVLDR_Cnt_EXV_TempElctrFlt_MFOP_Rx: nv-require-com-spec{init-value=0, variable=NeVLDR_Cnt_EXV_TempElctrFlt_MFOP}, required-interface=NeVLDR_Cnt_EXV_TempElctrFlt_MFOP
      NeVLDR_Cnt_EXV_TempSens_MFOP_Rx: nv-require-com-spec{init-value=0, variable=NeVLDR_Cnt_EXV_TempSens_MFOP}, required-interface=NeVLDR_Cnt_EXV_TempSens_MFOP
      NeVLDR_Cnt_HCTV_Leak_MFOP_Rx: nv-require-com-spec{init-value=0, variable=NeVLDR_Cnt_HCTV_Leak_MFOP}, required-interface=NeVLDR_Cnt_HCTV_Leak_MFOP
      NeVLDR_Cnt_HTL_PerfDiag_MFOP_Rx: nv-require-com-spec{init-value=0, variable=NeVLDR_Cnt_HTL_PerfDiag_MFOP}, required-interface=NeVLDR_Cnt_HTL_PerfDiag_MFOP
      NeVLDR_Cnt_HTSoV_StkCls_MFOP_Rx: nv-require-com-spec{init-value=0, variable=NeVLDR_Cnt_HTSoV_StkCls_MFOP}, required-interface=NeVLDR_Cnt_HTSoV_StkCls_MFOP
      NeVLDR_Cnt_HTSoV_StkOpn_MFOP_Rx: nv-require-com-spec{init-value=0, variable=NeVLDR_Cnt_HTSoV_StkOpn_MFOP}, required-interface=NeVLDR_Cnt_HTSoV_StkOpn_MFOP
      NeVLDR_Cnt_LTR_PerfDiag_MFOP_Rx: nv-require-com-spec{init-value=0, variable=NeVLDR_Cnt_LTR_PerfDiag_MFOP}, required-interface=NeVLDR_Cnt_LTR_PerfDiag_MFOP
      NeVLDR_Cnt_LTSOV_StkOff_MFOP_Rx: nv-require-com-spec{init-value=0, variable=NeVLDR_Cnt_LTSOV_StkOff_MFOP}, required-interface=NeVLDR_Cnt_LTSOV_StkOff_MFOP
      NeVLDR_Cnt_LTSOV_StkOn_MFOP_Rx: nv-require-com-spec{init-value=0, variable=NeVLDR_Cnt_LTSOV_StkOn_MFOP}, required-interface=NeVLDR_Cnt_LTSOV_StkOn_MFOP
      NeVLDR_Cnt_OEXV_PerfDiag_MFOP_Rx: nv-require-com-spec{init-value=0, variable=NeVLDR_Cnt_OEXV_PerfDiag_MFOP}, required-interface=NeVLDR_Cnt_OEXV_PerfDiag_MFOP
      NeVLDR_Cnt_OEXV_PressElctrFlt_MFOP_Rx: nv-require-com-spec{init-value=0, variable=NeVLDR_Cnt_OEXV_PressElctrFlt_MFOP}, required-interface=NeVLDR_Cnt_OEXV_PressElctrFlt_MFOP
      NeVLDR_Cnt_OEXV_PressSens_MFOP_Rx: nv-require-com-spec{init-value=0, variable=NeVLDR_Cnt_OEXV_PressSens_MFOP}, required-interface=NeVLDR_Cnt_OEXV_PressSens_MFOP
      NeVLDR_Cnt_OEXV_TempElctrFlt_MFOP_Rx: nv-require-com-spec{init-value=0, variable=NeVLDR_Cnt_OEXV_TempElctrFlt_MFOP}, required-interface=NeVLDR_Cnt_OEXV_TempElctrFlt_MFOP
      NeVLDR_Cnt_CPV2_PerfDiag_MFOP_Rx: nv-require-com-spec{init-value=0, variable=NeVLDR_Cnt_CPV2_PerfDiag_MFOP}, required-interface=NeVLDR_Cnt_CPV2_PerfDiag_MFOP
      NeVLDR_Cnt_BHV_PerfDiag_MFOP_Rx: nv-require-com-spec{init-value=0, variable=NeVLDR_Cnt_BHV_PerfDiag_MFOP}, required-interface=NeVLDR_Cnt_BHV_PerfDiag_MFOP
    24 x provide port:
      NeVLDR_Cnt_CPV_PerfDiag_MFOP: nv-provide-com-spec{ram-block-init-value=0, variable=NeVLDR_Cnt_CPV_PerfDiag_MFOP}, provided-interface=NeVLDR_Cnt_CPV_PerfDiag_MFOP
      NeVLDR_Cnt_CabVlvOpeng_Err_MFOP: nv-provide-com-spec{ram-block-init-value=0, variable=NeVLDR_Cnt_CabVlvOpeng_Err_MFOP}, provided-interface=NeVLDR_Cnt_CabVlvOpeng_Err_MFOP
      NeVLDR_Cnt_EEXV_PerfDiag_MFOP: nv-provide-com-spec{ram-block-init-value=0, variable=NeVLDR_Cnt_EEXV_PerfDiag_MFOP}, provided-interface=NeVLDR_Cnt_EEXV_PerfDiag_MFOP
      NeVLDR_Cnt_EEXV_PressElctrFlt_MFOP: nv-provide-com-spec{ram-block-init-value=0, variable=NeVLDR_Cnt_EEXV_PressElctrFlt_MFOP}, provided-interface=NeVLDR_Cnt_EEXV_PressElctrFlt_MFOP
      NeVLDR_Cnt_EEXV_PressSens_MFOP: nv-provide-com-spec{ram-block-init-value=0, variable=NeVLDR_Cnt_EEXV_PressSens_MFOP}, provided-interface=NeVLDR_Cnt_EEXV_PressSens_MFOP
      NeVLDR_Cnt_EEXV_TempElctrFlt_MFOP: nv-provide-com-spec{ram-block-init-value=0, variable=NeVLDR_Cnt_EEXV_TempElctrFlt_MFOP}, provided-interface=NeVLDR_Cnt_EEXV_TempElctrFlt_MFOP
      NeVLDR_Cnt_EXV_PerfDiag_MFOP: nv-provide-com-spec{ram-block-init-value=0, variable=NeVLDR_Cnt_EXV_PerfDiag_MFOP}, provided-interface=NeVLDR_Cnt_EXV_PerfDiag_MFOP
      NeVLDR_Cnt_EXV_PressElctrFlt_MFOP: nv-provide-com-spec{ram-block-init-value=0, variable=NeVLDR_Cnt_EXV_PressElctrFlt_MFOP}, provided-interface=NeVLDR_Cnt_EXV_PressElctrFlt_MFOP
      NeVLDR_Cnt_EXV_PressSens_MFOP: nv-provide-com-spec{ram-block-init-value=0, variable=NeVLDR_Cnt_EXV_PressSens_MFOP}, provided-interface=NeVLDR_Cnt_EXV_PressSens_MFOP
      NeVLDR_Cnt_EXV_TempElctrFlt_MFOP: nv-provide-com-spec{ram-block-init-value=0, variable=NeVLDR_Cnt_EXV_TempElctrFlt_MFOP}, provided-interface=NeVLDR_Cnt_EXV_TempElctrFlt_MFOP
      NeVLDR_Cnt_EXV_TempSens_MFOP: nv-provide-com-spec{ram-block-init-value=0, variable=NeVLDR_Cnt_EXV_TempSens_MFOP}, provided-interface=NeVLDR_Cnt_EXV_TempSens_MFOP
      NeVLDR_Cnt_HCTV_Leak_MFOP: nv-provide-com-spec{ram-block-init-value=0, variable=NeVLDR_Cnt_HCTV_Leak_MFOP}, provided-interface=NeVLDR_Cnt_HCTV_Leak_MFOP
      NeVLDR_Cnt_HTL_PerfDiag_MFOP: nv-provide-com-spec{ram-block-init-value=0, variable=NeVLDR_Cnt_HTL_PerfDiag_MFOP}, provided-interface=NeVLDR_Cnt_HTL_PerfDiag_MFOP
      NeVLDR_Cnt_HTSoV_StkCls_MFOP: nv-provide-com-spec{ram-block-init-value=0, variable=NeVLDR_Cnt_HTSoV_StkCls_MFOP}, provided-interface=NeVLDR_Cnt_HTSoV_StkCls_MFOP
      NeVLDR_Cnt_HTSoV_StkOpn_MFOP: nv-provide-com-spec{ram-block-init-value=0, variable=NeVLDR_Cnt_HTSoV_StkOpn_MFOP}, provided-interface=NeVLDR_Cnt_HTSoV_StkOpn_MFOP
      NeVLDR_Cnt_LTR_PerfDiag_MFOP: nv-provide-com-spec{ram-block-init-value=0, variable=NeVLDR_Cnt_LTR_PerfDiag_MFOP}, provided-interface=NeVLDR_Cnt_LTR_PerfDiag_MFOP
      NeVLDR_Cnt_LTSOV_StkOff_MFOP: nv-provide-com-spec{ram-block-init-value=0, variable=NeVLDR_Cnt_LTSOV_StkOff_MFOP}, provided-interface=NeVLDR_Cnt_LTSOV_StkOff_MFOP
      NeVLDR_Cnt_LTSOV_StkOn_MFOP: nv-provide-com-spec{ram-block-init-value=0, variable=NeVLDR_Cnt_LTSOV_StkOn_MFOP}, provided-interface=NeVLDR_Cnt_LTSOV_StkOn_MFOP
      NeVLDR_Cnt_OEXV_PerfDiag_MFOP: nv-provide-com-spec{ram-block-init-value=0, variable=NeVLDR_Cnt_OEXV_PerfDiag_MFOP}, provided-interface=NeVLDR_Cnt_OEXV_PerfDiag_MFOP
      NeVLDR_Cnt_OEXV_PressElctrFlt_MFOP: nv-provide-com-spec{ram-block-init-value=0, variable=NeVLDR_Cnt_OEXV_PressElctrFlt_MFOP}, provided-interface=NeVLDR_Cnt_OEXV_PressElctrFlt_MFOP
      NeVLDR_Cnt_OEXV_PressSens_MFOP: nv-provide-com-spec{ram-block-init-value=0, variable=NeVLDR_Cnt_OEXV_PressSens_MFOP}, provided-interface=NeVLDR_Cnt_OEXV_PressSens_MFOP
      NeVLDR_Cnt_OEXV_TempElctrFlt_MFOP: nv-provide-com-spec{ram-block-init-value=0, variable=NeVLDR_Cnt_OEXV_TempElctrFlt_MFOP}, provided-interface=NeVLDR_Cnt_OEXV_TempElctrFlt_MFOP
      NeVLDR_Cnt_CPV2_PerfDiag_MFOP: nv-provide-com-spec{ram-block-init-value=0, variable=NeVLDR_Cnt_CPV2_PerfDiag_MFOP}, provided-interface=NeVLDR_Cnt_CPV2_PerfDiag_MFOP
      NeVLDR_Cnt_BHV_PerfDiag_MFOP: nv-provide-com-spec{ram-block-init-value=0, variable=NeVLDR_Cnt_BHV_PerfDiag_MFOP}, provided-interface=NeVLDR_Cnt_BHV_PerfDiag_MFOP
    behavior IB_VLDR: data-type-mapping=msADTtoIDTMapping, handle-termination-and-restart=NO-SUPPORT
      timing event Event_MedTED: start-on-event=VLDR_MedTED, period=0.02
      init event Event_VLDR_ac_Init: start-on-event=VLDR_ac_Init
      init event Event_PwrOn: start-on-event=VLDR_PwrOn
      init event Event_PwrOff: start-on-event=VLDR_PwrOff
      4 x runnable:
        VLDR_ac_Init
          data-send-points:
            24 x access:
              OUT_VeVLDR_e_FaultSts_HB_PSC_CtrlValACktPerf_Value: accessed-variable=VeVLDR_e_FaultSts_HB_PSC_CtrlValACktPerf.Value
              OUT_VeVLDR_e_FaultSts_AC_RefrigExpVlvAct_C_CntrlCktPerf_Value: accessed-variable=VeVLDR_e_FaultSts_AC_RefrigExpVlvAct_C_CntrlCktPerf.Value
              OUT_VeVLDR_e_FaultSts_AC_RefrigPresSnsrCCkt_Value: accessed-variable=VeVLDR_e_FaultSts_AC_RefrigPresSnsrCCkt.Value
              OUT_VeVLDR_e_FaultSts_AC_RefrigPresSnsrCCktPerf_Value: accessed-variable=VeVLDR_e_FaultSts_AC_RefrigPresSnsrCCktPerf.Value
              OUT_VeVLDR_e_FaultSts_AC_RefrigTempSnsrCCkt_Value: accessed-variable=VeVLDR_e_FaultSts_AC_RefrigTempSnsrCCkt.Value
              OUT_VeVLDR_e_FaultSts_CoolantVlvA_StkOpn_Value: accessed-variable=VeVLDR_e_FaultSts_CoolantVlvA_StkOpn.Value
              OUT_VeVLDR_e_FaultSts_CoolantVlvA_Perf_Value: accessed-variable=VeVLDR_e_FaultSts_CoolantVlvA_Perf.Value
              OUT_VeVLDR_e_FaultSts_HB_PSC_CtrlValCCktPerf_Value: accessed-variable=VeVLDR_e_FaultSts_HB_PSC_CtrlValCCktPerf.Value
              OUT_VeVLDR_e_FaultSts_CoolantVlvB_StkClsd_Value: accessed-variable=VeVLDR_e_FaultSts_CoolantVlvB_StkClsd.Value
              OUT_VeVLDR_e_FaultSts_CoolantVlvB_StkOpn_Value: accessed-variable=VeVLDR_e_FaultSts_CoolantVlvB_StkOpn.Value
              OUT_VeVLDR_e_FaultSts_HB_PSC_CtrlValBCktPerf_Value: accessed-variable=VeVLDR_e_FaultSts_HB_PSC_CtrlValBCktPerf.Value
              OUT_VeVLDR_e_FaultSts_HybEvBatPacCoolCtrlVlvBPerfStkOff_Value: accessed-variable=VeVLDR_e_FaultSts_HybEvBatPacCoolCtrlVlvBPerfStkOff.Value
              OUT_VeVLDR_e_FaultSts_HybEvBatPacCoolCtrlVlvBStkOn_Value: accessed-variable=VeVLDR_e_FaultSts_HybEvBatPacCoolCtrlVlvBStkOn.Value
              OUT_VeVLDR_e_FaultSts_AC_RefrigExpVlvActD_CntrlCktPerf_Value: accessed-variable=VeVLDR_e_FaultSts_AC_RefrigExpVlvActD_CntrlCktPerf.Value
              OUT_VeVLDR_e_FaultSts_AC_RefrigPresSnsrDCkt_Value: accessed-variable=VeVLDR_e_FaultSts_AC_RefrigPresSnsrDCkt.Value
              OUT_VeVLDR_e_FaultSts_AC_RefrigPresSnsrDCktPerf_Value: accessed-variable=VeVLDR_e_FaultSts_AC_RefrigPresSnsrDCktPerf.Value
              OUT_VeVLDR_e_FaultSts_AC_RefrigTempSnsrDCkt_Value: accessed-variable=VeVLDR_e_FaultSts_AC_RefrigTempSnsrDCkt.Value
              OUT_VeVLDR_e_FaultSts_AC_RefrigExpVlvActCtrCktPerf_Value: accessed-variable=VeVLDR_e_FaultSts_AC_RefrigExpVlvActCtrCktPerf.Value
              OUT_VeVLDR_e_FaultSts_AC_RefrigTempSnsrBCkt_Value: accessed-variable=VeVLDR_e_FaultSts_AC_RefrigTempSnsrBCkt.Value
              OUT_VeVLDR_e_FaultSts_AC_RefrigTempSnsrBPerf_Value: accessed-variable=VeVLDR_e_FaultSts_AC_RefrigTempSnsrBPerf.Value
              OUT_VeVLDR_e_FaultSts_AC_RefrigTempSnsrACkt_Value: accessed-variable=VeVLDR_e_FaultSts_AC_RefrigTempSnsrACkt.Value
              OUT_VeVLDR_e_FaultSts_AC_RefrigTempSnsrAPerf_Value: accessed-variable=VeVLDR_e_FaultSts_AC_RefrigTempSnsrAPerf.Value
              OUT_VeVLDR_e_FaultSts_EngCoolbypsVlvDPerf_Value: accessed-variable=VeVLDR_e_FaultSts_EngCoolbypsVlvDPerf.Value
              OUT_VeVLDR_e_FaultSts_HybPropSysCoolCntrlVal_E_Perf_Value: accessed-variable=VeVLDR_e_FaultSts_HybPropSysCoolCntrlVal_E_Perf.Value
        VLDR_MedTED
          data-receive-point-by-arguments:
            145 x access:
              IN_VeBPCR_b_BPCM_LIN_BusOff_FA_Value: accessed-variable=VeBPCR_b_BPCM_LIN_BusOff_FA.Value, variation-point={short-label=vpIN_VeBPCR_b_BPCM_LIN_BusOff_FA_Value, sw-syscond=1}
              IN_VeBPCR_b_BPCM_LIN_BusOff_SgnlRcvd_Value: accessed-variable=VeBPCR_b_BPCM_LIN_BusOff_SgnlRcvd.Value, variation-point={short-label=vpIN_VeBPCR_b_BPCM_LIN_BusOff_SgnlRcvd_Value, sw-syscond=1}
              IN_VeBPCR_b_BPCM_LOC_BCP_FA_Value: accessed-variable=VeBPCR_b_BPCM_LOC_BCP_FA.Value, variation-point={short-label=vpIN_VeBPCR_b_BPCM_LOC_BCP_FA_Value, sw-syscond=1}
              IN_VeBPCR_b_BPCM_LOC_BCP_SgnlRcvd_Value: accessed-variable=VeBPCR_b_BPCM_LOC_BCP_SgnlRcvd.Value, variation-point={short-label=vpIN_VeBPCR_b_BPCM_LOC_BCP_SgnlRcvd_Value, sw-syscond=1}
              IN_VeBPCR_e_BPCM_LIN_BusOff_Value: accessed-variable=VeBPCR_e_BPCM_LIN_BusOff.Value, variation-point={short-label=vpIN_VeBPCR_e_BPCM_LIN_BusOff_Value, sw-syscond=1}
              IN_VeBPCR_e_BPCM_LOC_BCP_Value: accessed-variable=VeBPCR_e_BPCM_LOC_BCP.Value, variation-point={short-label=vpIN_VeBPCR_e_BPCM_LOC_BCP_Value, sw-syscond=1}
              IN_VeDFIR_b_DsblDiagFailSafe_Value: accessed-variable=VeDFIR_b_DsblDiagFailSafe.Value, variation-point={short-label=vpIN_VeDFIR_b_DsblDiagFailSafe_Value, sw-syscond=1}
              IN_VeDFIR_b_IsDiagGlobalConditionsValid_Value: accessed-variable=VeDFIR_b_IsDiagGlobalConditionsValid.Value, variation-point={short-label=vpIN_VeDFIR_b_IsDiagGlobalConditionsValid_Value, sw-syscond=1}
              IN_VeDFIR_b_PostCodeClrDiagDsbl_Value: accessed-variable=VeDFIR_b_PostCodeClrDiagDsbl.Value, variation-point={short-label=vpIN_VeDFIR_b_PostCodeClrDiagDsbl_Value, sw-syscond=1}
              IN_VeDMAB_y_StatusByte_AC_RefrigExpVlvActCtrCktPerf_Value: accessed-variable=VeDMAB_y_StatusByte_AC_RefrigExpVlvActCtrCktPerf.Value
              IN_VeDMAB_y_StatusByte_AC_RefrigExpVlvActD_CntrlCktPerf_Value: accessed-variable=VeDMAB_y_StatusByte_AC_RefrigExpVlvActD_CntrlCktPerf.Value
              IN_VeDMAB_y_StatusByte_AC_RefrigExpVlvAct_C_CntrlCktPerf_Value: accessed-variable=VeDMAB_y_StatusByte_AC_RefrigExpVlvAct_C_CntrlCktPerf.Value
              IN_VeDMAB_y_StatusByte_AC_RefrigPresSnsrAHi_Value: accessed-variable=VeDMAB_y_StatusByte_AC_RefrigPresSnsrAHi.Value
              IN_VeDMAB_y_StatusByte_AC_RefrigPresSnsrALo_Value: accessed-variable=VeDMAB_y_StatusByte_AC_RefrigPresSnsrALo.Value
              IN_VeDMAB_y_StatusByte_AC_RefrigPresSnsrAPerf_Value: accessed-variable=VeDMAB_y_StatusByte_AC_RefrigPresSnsrAPerf.Value
              IN_VeDMAB_y_StatusByte_AC_RefrigPresSnsrCCkt_Value: accessed-variable=VeDMAB_y_StatusByte_AC_RefrigPresSnsrCCkt.Value
              IN_VeDMAB_y_StatusByte_AC_RefrigPresSnsrCCktPerf_Value: accessed-variable=VeDMAB_y_StatusByte_AC_RefrigPresSnsrCCktPerf.Value
              IN_VeDMAB_y_StatusByte_AC_RefrigPresSnsrDCkt_Value: accessed-variable=VeDMAB_y_StatusByte_AC_RefrigPresSnsrDCkt.Value
              IN_VeDMAB_y_StatusByte_AC_RefrigPresSnsrDCktPerf_Value: accessed-variable=VeDMAB_y_StatusByte_AC_RefrigPresSnsrDCktPerf.Value
              IN_VeDMAB_y_StatusByte_AC_RefrigTempSnsr4CktPerf_Value: accessed-variable=VeDMAB_y_StatusByte_AC_RefrigTempSnsr4CktPerf.Value
              IN_VeDMAB_y_StatusByte_AC_RefrigTempSnsrACkt_Value: accessed-variable=VeDMAB_y_StatusByte_AC_RefrigTempSnsrACkt.Value
              IN_VeDMAB_y_StatusByte_AC_RefrigTempSnsrAPerf_Value: accessed-variable=VeDMAB_y_StatusByte_AC_RefrigTempSnsrAPerf.Value
              IN_VeDMAB_y_StatusByte_AC_RefrigTempSnsrBCkt_Value: accessed-variable=VeDMAB_y_StatusByte_AC_RefrigTempSnsrBCkt.Value
              IN_VeDMAB_y_StatusByte_AC_RefrigTempSnsrBPerf_Value: accessed-variable=VeDMAB_y_StatusByte_AC_RefrigTempSnsrBPerf.Value
              IN_VeDMAB_y_StatusByte_AC_RefrigTempSnsrCCkt_Value: accessed-variable=VeDMAB_y_StatusByte_AC_RefrigTempSnsrCCkt.Value
              IN_VeDMAB_y_StatusByte_AC_RefrigTempSnsrCPerf_Value: accessed-variable=VeDMAB_y_StatusByte_AC_RefrigTempSnsrCPerf.Value
              IN_VeDMAB_y_StatusByte_AC_RefrigTempSnsrDCkt_Value: accessed-variable=VeDMAB_y_StatusByte_AC_RefrigTempSnsrDCkt.Value
              IN_VeDMAB_y_StatusByte_BattCoolPmpATempSnsrPerf_Value: accessed-variable=VeDMAB_y_StatusByte_BattCoolPmpATempSnsrPerf.Value
              IN_VeDMAB_y_StatusByte_BattCoolPmpOveSpd_Value: accessed-variable=VeDMAB_y_StatusByte_BattCoolPmpOveSpd.Value
              IN_VeDMAB_y_StatusByte_BattCoolPmpPerf_Value: accessed-variable=VeDMAB_y_StatusByte_BattCoolPmpPerf.Value
              IN_VeDMAB_y_StatusByte_CT_SnsrCktHi_Value: accessed-variable=VeDMAB_y_StatusByte_CT_SnsrCktHi.Value
              IN_VeDMAB_y_StatusByte_CT_SnsrCktLo_Value: accessed-variable=VeDMAB_y_StatusByte_CT_SnsrCktLo.Value
              IN_VeDMAB_y_StatusByte_CT_SnsrPerf_Value: accessed-variable=VeDMAB_y_StatusByte_CT_SnsrPerf.Value
              IN_VeDMAB_y_StatusByte_CommBusOff_Value: accessed-variable=VeDMAB_y_StatusByte_CommBusOff.Value
              IN_VeDMAB_y_StatusByte_CommBus_B_Off_Value: accessed-variable=VeDMAB_y_StatusByte_CommBus_B_Off.Value
              IN_VeDMAB_y_StatusByte_CoolOutTempSnsCkt_Value: accessed-variable=VeDMAB_y_StatusByte_CoolOutTempSnsCkt.Value
              IN_VeDMAB_y_StatusByte_CoolantVlvA_Ckt_Value: accessed-variable=VeDMAB_y_StatusByte_CoolantVlvA_Ckt.Value
              IN_VeDMAB_y_StatusByte_CoolantVlvA_CktHi_Value: accessed-variable=VeDMAB_y_StatusByte_CoolantVlvA_CktHi.Value
              IN_VeDMAB_y_StatusByte_CoolantVlvA_CktLo_Value: accessed-variable=VeDMAB_y_StatusByte_CoolantVlvA_CktLo.Value
              IN_VeDMAB_y_StatusByte_CoolantVlvA_FdbkCktHi_Value: accessed-variable=VeDMAB_y_StatusByte_CoolantVlvA_FdbkCktHi.Value
              IN_VeDMAB_y_StatusByte_CoolantVlvA_FdbkCktLo_Value: accessed-variable=VeDMAB_y_StatusByte_CoolantVlvA_FdbkCktLo.Value
              IN_VeDMAB_y_StatusByte_CoolantVlvB_Ckt_Value: accessed-variable=VeDMAB_y_StatusByte_CoolantVlvB_Ckt.Value
              IN_VeDMAB_y_StatusByte_CoolantVlvB_CktHi_Value: accessed-variable=VeDMAB_y_StatusByte_CoolantVlvB_CktHi.Value
              IN_VeDMAB_y_StatusByte_CoolantVlvB_CktLo_Value: accessed-variable=VeDMAB_y_StatusByte_CoolantVlvB_CktLo.Value
              IN_VeDMAB_y_StatusByte_CoolantVlvB_StkClsd_Value: accessed-variable=VeDMAB_y_StatusByte_CoolantVlvB_StkClsd.Value
              IN_VeDMAB_y_StatusByte_CoolantVlvB_StkOpn_Value: accessed-variable=VeDMAB_y_StatusByte_CoolantVlvB_StkOpn.Value
              IN_VeDMAB_y_StatusByte_EACPerf_Value: accessed-variable=VeDMAB_y_StatusByte_EACPerf.Value
              IN_VeDMAB_y_StatusByte_EngCoolbypsVlvDPerf_Value: accessed-variable=VeDMAB_y_StatusByte_EngCoolbypsVlvDPerf.Value
              IN_VeDMAB_y_StatusByte_HB_CT_SnsrPerf_Value: accessed-variable=VeDMAB_y_StatusByte_HB_CT_SnsrPerf.Value
              IN_VeDMAB_y_StatusByte_HB_PSC_CtrlValACktPerf_Value: accessed-variable=VeDMAB_y_StatusByte_HB_PSC_CtrlValACktPerf.Value
              IN_VeDMAB_y_StatusByte_HB_PSC_CtrlValBCktPerf_Value: accessed-variable=VeDMAB_y_StatusByte_HB_PSC_CtrlValBCktPerf.Value
              IN_VeDMAB_y_StatusByte_HB_PSC_CtrlValCCktPerf_Value: accessed-variable=VeDMAB_y_StatusByte_HB_PSC_CtrlValCCktPerf.Value
              IN_VeDMAB_y_StatusByte_HybBattCooTempSnsrCPer_Value: accessed-variable=VeDMAB_y_StatusByte_HybBattCooTempSnsrCPer.Value
              IN_VeDMAB_y_StatusByte_HybBattCooTempSnsrDPer_Value: accessed-variable=VeDMAB_y_StatusByte_HybBattCooTempSnsrDPer.Value
              IN_VeDMAB_y_StatusByte_HybEvBatPacCoolCtrlVlv2CtrlCktHi_Value: accessed-variable=VeDMAB_y_StatusByte_HybEvBatPacCoolCtrlVlv2CtrlCktHi.Value
              IN_VeDMAB_y_StatusByte_HybEvBatPacCoolCtrlVlv2CtrlCktLo_Value: accessed-variable=VeDMAB_y_StatusByte_HybEvBatPacCoolCtrlVlv2CtrlCktLo.Value
              IN_VeDMAB_y_StatusByte_HybEvBatPacCoolCtrlVlvBPerfStkOff_Value: accessed-variable=VeDMAB_y_StatusByte_HybEvBatPacCoolCtrlVlvBPerfStkOff.Value
              IN_VeDMAB_y_StatusByte_HybEvBatPacCoolCtrlVlvBStkOn_Value: accessed-variable=VeDMAB_y_StatusByte_HybEvBatPacCoolCtrlVlvBStkOn.Value
              IN_VeDMAB_y_StatusByte_HybPropSysCoolCntrlVal_E_Perf_Value: accessed-variable=VeDMAB_y_StatusByte_HybPropSysCoolCntrlVal_E_Perf.Value
              IN_VeDMAB_y_StatusByte_InvData_BECM_Value: accessed-variable=VeDMAB_y_StatusByte_InvData_BECM.Value
              IN_VeDMAB_y_StatusByte_InvData_BECM_CANC11_Value: accessed-variable=VeDMAB_y_StatusByte_InvData_BECM_CANC11.Value
              IN_VeDMAB_y_StatusByte_LIN{1..3}_BusOff_Value: accessed-variable=VeDMAB_y_StatusByte_LIN{1..3}_BusOff.Value
              IN_VeDMAB_y_StatusByte_LosCommBECM_A_Value: accessed-variable=VeDMAB_y_StatusByte_LosCommBECM_A.Value
              IN_VeDMAB_y_StatusByte_LosCommBECM_A_CANC11_Value: accessed-variable=VeDMAB_y_StatusByte_LosCommBECM_A_CANC11.Value
              IN_VeDMAB_y_StatusByte_LosCommHybPSCCtrlValA_Value: accessed-variable=VeDMAB_y_StatusByte_LosCommHybPSCCtrlValA.Value
              IN_VeDMAB_y_StatusByte_LostCommACRefrigExpVlvActA_Value: accessed-variable=VeDMAB_y_StatusByte_LostCommACRefrigExpVlvActA.Value
              IN_VeDMAB_y_StatusByte_LostCommACRefrigExpVlvActC_Value: accessed-variable=VeDMAB_y_StatusByte_LostCommACRefrigExpVlvActC.Value
              IN_VeDMAB_y_StatusByte_LostCommACRefrigExpVlvActD_Value: accessed-variable=VeDMAB_y_StatusByte_LostCommACRefrigExpVlvActD.Value
              IN_VeDMAB_y_StatusByte_LostCommCoolHtrA_Value: accessed-variable=VeDMAB_y_StatusByte_LostCommCoolHtrA.Value
              IN_VeDMAB_y_StatusByte_LostCommEAC_Value: accessed-variable=VeDMAB_y_StatusByte_LostCommEAC.Value
              IN_VeDMAB_y_StatusByte_LostCommEngCoolbypsVlvD_Value: accessed-variable=VeDMAB_y_StatusByte_LostCommEngCoolbypsVlvD.Value
              IN_VeDMAB_y_StatusByte_LostCommHB_PSCCooCtrlVlvB_Value: accessed-variable=VeDMAB_y_StatusByte_LostCommHB_PSCCooCtrlVlvB.Value
              IN_VeDMAB_y_StatusByte_LostCommHB_PSCCooCtrlVlvC_Value: accessed-variable=VeDMAB_y_StatusByte_LostCommHB_PSCCooCtrlVlvC.Value
              IN_VeDMAB_y_StatusByte_LostComm_HybPropSysCoolCntrlVal_E_Value: accessed-variable=VeDMAB_y_StatusByte_LostComm_HybPropSysCoolCntrlVal_E.Value
              IN_VeDMAB_y_StatusByte_MtrElect_CT_SnsrCktHi_Value: accessed-variable=VeDMAB_y_StatusByte_MtrElect_CT_SnsrCktHi.Value
              IN_VeDMAB_y_StatusByte_MtrElect_CT_SnsrCktLo_Value: accessed-variable=VeDMAB_y_StatusByte_MtrElect_CT_SnsrCktLo.Value
              IN_VeDMAB_y_StatusByte_MtrElect_CT_SnsrPerf_Value: accessed-variable=VeDMAB_y_StatusByte_MtrElect_CT_SnsrPerf.Value
              IN_VeDMAB_y_StatusByte_MtrElect_CoolPumBCtrlPerf_Value: accessed-variable=VeDMAB_y_StatusByte_MtrElect_CoolPumBCtrlPerf.Value
              IN_VeDMAB_y_StatusByte_ThrmlRlyCtrlCkt_Value: accessed-variable=VeDMAB_y_StatusByte_ThrmlRlyCtrlCkt.Value
              IN_VeENGR_T_EngCoolantTemp_Value: accessed-variable=VeENGR_T_EngCoolantTemp.Value, variation-point={short-label=vpIN_VeENGR_T_EngCoolantTemp_Value, sw-syscond=1}
              IN_VeENGR_b_ECT_Sgnl_Rcvd_Value: accessed-variable=VeENGR_b_ECT_Sgnl_Rcvd.Value, variation-point={short-label=vpIN_VeENGR_b_ECT_Sgnl_Rcvd_Value, sw-syscond=1}
              IN_VeENGR_b_ECT_SnsrFA_Value: accessed-variable=VeENGR_b_ECT_SnsrFA.Value, variation-point={short-label=vpIN_VeENGR_b_ECT_SnsrFA_Value, sw-syscond=1}
              IN_VeENGR_b_EngCombustionCmnd_Value: accessed-variable=VeENGR_b_EngCombustionCmnd.Value, variation-point={short-label=vpIN_VeENGR_b_EngCombustionCmnd_Value, sw-syscond=1}
              IN_VeESSR_e_EngStrtStpMd_Value: accessed-variable=VeESSR_e_EngStrtStpMd.Value, variation-point={short-label=vpIN_VeESSR_e_EngStrtStpMd_Value, sw-syscond=1}
              IN_VeHPMR_b_PropSysActv_Value: accessed-variable=VeHPMR_b_PropSysActv.Value, variation-point={short-label=vpIN_VeHPMR_b_PropSysActv_Value, sw-syscond=1}
              IN_VeIDCR_U_IBS_BattVolt_Value: accessed-variable=VeIDCR_U_IBS_BattVolt.Value, variation-point={short-label=vpIN_VeIDCR_U_IBS_BattVolt_Value, sw-syscond=1}
              IN_VePLTR_b_HCPOffTimeFA_Value: accessed-variable=VePLTR_b_HCPOffTimeFA.Value, variation-point={short-label=vpIN_VePLTR_b_HCPOffTimeFA_Value, sw-syscond=1}
              IN_VePLTR_t_HCPOffTime_Value: accessed-variable=VePLTR_t_HCPOffTime.Value, variation-point={short-label=vpIN_VePLTR_t_HCPOffTime_Value, sw-syscond=1}
              IN_VePMDR_U_BF1_SysVolt_Value: accessed-variable=VePMDR_U_BF1_SysVolt.Value, variation-point={short-label=vpIN_VePMDR_U_BF1_SysVolt_Value, sw-syscond=1}
              IN_VePMTR_e_ThrmlDevEnbl_Value: accessed-variable=VePMTR_e_ThrmlDevEnbl.Value, variation-point={short-label=vpIN_VePMTR_e_ThrmlDevEnbl_Value, sw-syscond=1}
              IN_VeRCVR_Pct_EEXV_Cmd_Value: accessed-variable=VeRCVR_Pct_EEXV_Cmd.Value, variation-point={short-label=vpIN_VeRCVR_Pct_EEXV_Cmd_Value, sw-syscond=1}
              IN_VeRCVR_Pct_EXV_PosRq_Value: accessed-variable=VeRCVR_Pct_EXV_PosRq.Value, variation-point={short-label=vpIN_VeRCVR_Pct_EXV_PosRq_Value, sw-syscond=1}
              IN_VeRCVR_Pct_FrWyVlv_PstnCmnd_Value: accessed-variable=VeRCVR_Pct_FrWyVlv_PstnCmnd.Value, variation-point={short-label=vpIN_VeRCVR_Pct_FrWyVlv_PstnCmnd_Value, sw-syscond=1}
              IN_VeRCVR_Pct_HTL_Vlv_PstnCmnd_Value: accessed-variable=VeRCVR_Pct_HTL_Vlv_PstnCmnd.Value, variation-point={short-label=vpIN_VeRCVR_Pct_HTL_Vlv_PstnCmnd_Value, sw-syscond=1}
              IN_VeRCVR_Pct_HtrCoreBypVlv_PstnCmnd_Value: accessed-variable=VeRCVR_Pct_HtrCoreBypVlv_PstnCmnd.Value, variation-point={short-label=vpIN_VeRCVR_Pct_HtrCoreBypVlv_PstnCmnd_Value, sw-syscond=1}
              IN_VeRCVR_Pct_LTR_Vlv_PstnCmnd_Value: accessed-variable=VeRCVR_Pct_LTR_Vlv_PstnCmnd.Value, variation-point={short-label=vpIN_VeRCVR_Pct_LTR_Vlv_PstnCmnd_Value, sw-syscond=1}
              IN_VeRCVR_Pct_OEXV_Cmd_Value: accessed-variable=VeRCVR_Pct_OEXV_Cmd.Value, variation-point={short-label=vpIN_VeRCVR_Pct_OEXV_Cmd_Value, sw-syscond=1}
              IN_VeRCVR_b_FrWyVlv_PstnSv_Value: accessed-variable=VeRCVR_b_FrWyVlv_PstnSv.Value, variation-point={short-label=vpIN_VeRCVR_b_FrWyVlv_PstnSv_Value, sw-syscond=1}
              IN_VeTAIR_Pct_CPV2_PstnAct_Value: accessed-variable=VeTAIR_Pct_CPV2_PstnAct.Value, variation-point={short-label=vpIN_VeTAIR_Pct_CPV2_PstnAct_Value, sw-syscond=1}
              IN_VeTAIR_Pct_EEXV_PosAct_Value: accessed-variable=VeTAIR_Pct_EEXV_PosAct.Value, variation-point={short-label=vpIN_VeTAIR_Pct_EEXV_PosAct_Value, sw-syscond=1}
              IN_VeTAIR_Pct_EXV_PosAct_Value: accessed-variable=VeTAIR_Pct_EXV_PosAct.Value, variation-point={short-label=vpIN_VeTAIR_Pct_EXV_PosAct_Value, sw-syscond=1}
              IN_VeTAIR_Pct_FrWyVlv_PstnAct_Value: accessed-variable=VeTAIR_Pct_FrWyVlv_PstnAct.Value, variation-point={short-label=vpIN_VeTAIR_Pct_FrWyVlv_PstnAct_Value, sw-syscond=1}
              IN_VeTAIR_Pct_HTL_BypsVlv_ActlPstn_Value: accessed-variable=VeTAIR_Pct_HTL_BypsVlv_ActlPstn.Value, variation-point={short-label=vpIN_VeTAIR_Pct_HTL_BypsVlv_ActlPstn_Value, sw-syscond=1}
              IN_VeTAIR_Pct_LTR_BypsVlv_ActlPstn_Value: accessed-variable=VeTAIR_Pct_LTR_BypsVlv_ActlPstn.Value, variation-point={short-label=vpIN_VeTAIR_Pct_LTR_BypsVlv_ActlPstn_Value, sw-syscond=1}
              IN_VeTAIR_Pct_OEXV_PosAct_Value: accessed-variable=VeTAIR_Pct_OEXV_PosAct.Value, variation-point={short-label=vpIN_VeTAIR_Pct_OEXV_PosAct_Value, sw-syscond=1}
              IN_VeTAIR_T_EEXV_RefTemp_Value: accessed-variable=VeTAIR_T_EEXV_RefTemp.Value, variation-point={short-label=vpIN_VeTAIR_T_EEXV_RefTemp_Value, sw-syscond=1}
              IN_VeTAIR_T_EXV_RefTemp_Value: accessed-variable=VeTAIR_T_EXV_RefTemp.Value, variation-point={short-label=vpIN_VeTAIR_T_EXV_RefTemp_Value, sw-syscond=1}
              IN_VeTAIR_T_OEXV_RefTemp_Value: accessed-variable=VeTAIR_T_OEXV_RefTemp.Value, variation-point={short-label=vpIN_VeTAIR_T_OEXV_RefTemp_Value, sw-syscond=1}
              IN_VeTAIR_b_EEXV_PosAct_FA_Value: accessed-variable=VeTAIR_b_EEXV_PosAct_FA.Value, variation-point={short-label=vpIN_VeTAIR_b_EEXV_PosAct_FA_Value, sw-syscond=1}
              IN_VeTAIR_b_EEXV_RefPress_FA_Value: accessed-variable=VeTAIR_b_EEXV_RefPress_FA.Value, variation-point={short-label=vpIN_VeTAIR_b_EEXV_RefPress_FA_Value, sw-syscond=1}
              IN_VeTAIR_b_EXV_PosAct_FA_Value: accessed-variable=VeTAIR_b_EXV_PosAct_FA.Value, variation-point={short-label=vpIN_VeTAIR_b_EXV_PosAct_FA_Value, sw-syscond=1}
              IN_VeTAIR_b_EXV_RefPress_FA_Value: accessed-variable=VeTAIR_b_EXV_RefPress_FA.Value, variation-point={short-label=vpIN_VeTAIR_b_EXV_RefPress_FA_Value, sw-syscond=1}
              IN_VeTAIR_b_EXV_RefTemp_FA_Value: accessed-variable=VeTAIR_b_EXV_RefTemp_FA.Value, variation-point={short-label=vpIN_VeTAIR_b_EXV_RefTemp_FA_Value, sw-syscond=1}
              IN_VeTAIR_b_FrWyVlv_BlckPnt_Value: accessed-variable=VeTAIR_b_FrWyVlv_BlckPnt.Value, variation-point={short-label=vpIN_VeTAIR_b_FrWyVlv_BlckPnt_Value, sw-syscond=1}
              IN_VeTAIR_b_FrWyVlv_MechBrk_Value: accessed-variable=VeTAIR_b_FrWyVlv_MechBrk.Value, variation-point={short-label=vpIN_VeTAIR_b_FrWyVlv_MechBrk_Value, sw-syscond=1}
              IN_VeTAIR_b_FrWyVlv_OvrVltg_Value: accessed-variable=VeTAIR_b_FrWyVlv_OvrVltg.Value, variation-point={short-label=vpIN_VeTAIR_b_FrWyVlv_OvrVltg_Value, sw-syscond=1}
              IN_VeTAIR_b_FrWyVlv_PstnAct_FA_Value: accessed-variable=VeTAIR_b_FrWyVlv_PstnAct_FA.Value, variation-point={short-label=vpIN_VeTAIR_b_FrWyVlv_PstnAct_FA_Value, sw-syscond=1}
              IN_VeTAIR_b_FrWyVlv_RsErr_Value: accessed-variable=VeTAIR_b_FrWyVlv_RsErr.Value, variation-point={short-label=vpIN_VeTAIR_b_FrWyVlv_RsErr_Value, sw-syscond=1}
              IN_VeTAIR_b_FrWyVlv_ThrmlWrng_Value: accessed-variable=VeTAIR_b_FrWyVlv_ThrmlWrng.Value, variation-point={short-label=vpIN_VeTAIR_b_FrWyVlv_ThrmlWrng_Value, sw-syscond=1}
              IN_VeTAIR_b_FrWyVlv_UndrVltg_Value: accessed-variable=VeTAIR_b_FrWyVlv_UndrVltg.Value, variation-point={short-label=vpIN_VeTAIR_b_FrWyVlv_UndrVltg_Value, sw-syscond=1}
              IN_VeTAIR_b_HTL_BypsVlv_ActlPstn_FA_Value: accessed-variable=VeTAIR_b_HTL_BypsVlv_ActlPstn_FA.Value, variation-point={short-label=vpIN_VeTAIR_b_HTL_BypsVlv_ActlPstn_FA_Value, sw-syscond=1}
              IN_VeTAIR_b_LTR_BypsVlv_ActlPstn_FA_Value: accessed-variable=VeTAIR_b_LTR_BypsVlv_ActlPstn_FA.Value, variation-point={short-label=vpIN_VeTAIR_b_LTR_BypsVlv_ActlPstn_FA_Value, sw-syscond=1}
              IN_VeTAIR_b_OEXV_PosAct_FA_Value: accessed-variable=VeTAIR_b_OEXV_PosAct_FA.Value, variation-point={short-label=vpIN_VeTAIR_b_OEXV_PosAct_FA_Value, sw-syscond=1}
              IN_VeTAIR_b_OEXV_RefPress_FA_Value: accessed-variable=VeTAIR_b_OEXV_RefPress_FA.Value, variation-point={short-label=vpIN_VeTAIR_b_OEXV_RefPress_FA_Value, sw-syscond=1}
              IN_VeTAIR_b_WinshldDfrst_Value: accessed-variable=VeTAIR_b_WinshldDfrst.Value, variation-point={short-label=vpIN_VeTAIR_b_WinshldDfrst_Value, sw-syscond=1}
              IN_VeTAIR_e_CPV2_CalSts_Value: accessed-variable=VeTAIR_e_CPV2_CalSts.Value, variation-point={short-label=vpIN_VeTAIR_e_CPV2_CalSts_Value, sw-syscond=1}
              IN_VeTAIR_e_CompStat_Value: accessed-variable=VeTAIR_e_CompStat.Value, variation-point={short-label=vpIN_VeTAIR_e_CompStat_Value, sw-syscond=1}
              IN_VeTAIR_e_EEXV_CalStat_Value: accessed-variable=VeTAIR_e_EEXV_CalStat.Value, variation-point={short-label=vpIN_VeTAIR_e_EEXV_CalStat_Value, sw-syscond=1}
              IN_VeTAIR_e_EXV_CalStat_Value: accessed-variable=VeTAIR_e_EXV_CalStat.Value, variation-point={short-label=vpIN_VeTAIR_e_EXV_CalStat_Value, sw-syscond=1}
              IN_VeTAIR_e_FrWyVlv_CalSts_Value: accessed-variable=VeTAIR_e_FrWyVlv_CalSts.Value, variation-point={short-label=vpIN_VeTAIR_e_FrWyVlv_CalSts_Value, sw-syscond=1}
              IN_VeTAIR_e_OEXV_CalStat_Value: accessed-variable=VeTAIR_e_OEXV_CalStat.Value, variation-point={short-label=vpIN_VeTAIR_e_OEXV_CalStat_Value, sw-syscond=1}
              IN_VeTAIR_n_CompSpdFdb_Value: accessed-variable=VeTAIR_n_CompSpdFdb.Value, variation-point={short-label=vpIN_VeTAIR_n_CompSpdFdb_Value, sw-syscond=1}
              IN_VeTAIR_p_EEXV_RefPress_Value: accessed-variable=VeTAIR_p_EEXV_RefPress.Value, variation-point={short-label=vpIN_VeTAIR_p_EEXV_RefPress_Value, sw-syscond=1}
              IN_VeTAIR_p_EXV_RefPress_Value: accessed-variable=VeTAIR_p_EXV_RefPress.Value, variation-point={short-label=vpIN_VeTAIR_p_EXV_RefPress_Value, sw-syscond=1}
              IN_VeTAIR_p_OEXV_RefPress_Value: accessed-variable=VeTAIR_p_OEXV_RefPress.Value, variation-point={short-label=vpIN_VeTAIR_p_OEXV_RefPress_Value, sw-syscond=1}
              IN_VeTHMR_e_BatThrmlSt_Value: accessed-variable=VeTHMR_e_BatThrmlSt.Value, variation-point={short-label=vpIN_VeTHMR_e_BatThrmlSt_Value, sw-syscond=1}
              IN_VeTMIR_b_MainRly_CmdReq_Value: accessed-variable=VeTMIR_b_MainRly_CmdReq.Value, variation-point={short-label=vpIN_VeTMIR_b_MainRly_CmdReq_Value, sw-syscond=1}
              IN_VeTMIR_b_OnBrdChrg_ClntTmpIn_FA_Value: accessed-variable=VeTMIR_b_OnBrdChrg_ClntTmpIn_FA.Value, variation-point={short-label=vpIN_VeTMIR_b_OnBrdChrg_ClntTmpIn_FA_Value, sw-syscond=1}
              IN_VeTMIR_b_PsvPmpClnt_TmpIn_FA_Value: accessed-variable=VeTMIR_b_PsvPmpClnt_TmpIn_FA.Value, variation-point={short-label=vpIN_VeTMIR_b_PsvPmpClnt_TmpIn_FA_Value, sw-syscond=1}
              IN_VeTRIR_T_HV_BatClntTmp2_In_Value: accessed-variable=VeTRIR_T_HV_BatClntTmp2_In.Value, variation-point={short-label=vpIN_VeTRIR_T_HV_BatClntTmp2_In_Value, sw-syscond=1}
              IN_VeTRIR_T_HV_BatClntTmpOut_Value: accessed-variable=VeTRIR_T_HV_BatClntTmpOut.Value, variation-point={short-label=vpIN_VeTRIR_T_HV_BatClntTmpOut_Value, sw-syscond=1}
              IN_VeTRIR_T_HV_BatClntTmpOut2_Value: accessed-variable=VeTRIR_T_HV_BatClntTmpOut2.Value, variation-point={short-label=vpIN_VeTRIR_T_HV_BatClntTmpOut2_Value, sw-syscond=1}
              IN_VeTRIR_T_HV_BatClntTmp_In_Value: accessed-variable=VeTRIR_T_HV_BatClntTmp_In.Value, variation-point={short-label=vpIN_VeTRIR_T_HV_BatClntTmp_In_Value, sw-syscond=1}
          data-send-points:
            70 x access:
              OUT_VeVLDR_b_HTCV_Leak_DiagEnbl_Value: accessed-variable=VeVLDR_b_HTCV_Leak_DiagEnbl.Value
              OUT_VeVLDR_b_IUMPR_HTSOV_StkClsd_Value: accessed-variable=VeVLDR_b_IUMPR_HTSOV_StkClsd.Value
              OUT_VeVLDR_b_IUMPR_HTSOV_StkOpn_Value: accessed-variable=VeVLDR_b_IUMPR_HTSOV_StkOpn.Value
              OUT_VeVLDR_b_IUMPR_HTCV_Perf_Value: accessed-variable=VeVLDR_b_IUMPR_HTCV_Perf.Value
              OUT_VeVLDR_b_IUMPR_HTCV_Leak_Value: accessed-variable=VeVLDR_b_IUMPR_HTCV_Leak.Value
              OUT_VeVLDR_b_IUMPR_HTSOV_MinCmdThrshld_Met_Value: accessed-variable=VeVLDR_b_IUMPR_HTSOV_MinCmdThrshld_Met.Value
              OUT_VeVLDR_b_IUMPR_HTCV_MinCmdThrshld_Met_Value: accessed-variable=VeVLDR_b_IUMPR_HTCV_MinCmdThrshld_Met.Value
              OUT_VeVLDR_b_HTSoV_StkCls_XYEnbl_Value: accessed-variable=VeVLDR_b_HTSoV_StkCls_XYEnbl.Value
              OUT_VeVLDR_b_HTSoV_StkOpn_XYEnbl_Value: accessed-variable=VeVLDR_b_HTSoV_StkOpn_XYEnbl.Value
              OUT_VeVLDR_b_HTSoV_StkCls_FltDtct_Value: accessed-variable=VeVLDR_b_HTSoV_StkCls_FltDtct.Value
              OUT_VeVLDR_b_HTSoV_StkOpn_FltDtct_Value: accessed-variable=VeVLDR_b_HTSoV_StkOpn_FltDtct.Value
              OUT_VeVLDR_b_HTCV_Stck_FltDtct_Value: accessed-variable=VeVLDR_b_HTCV_Stck_FltDtct.Value
              OUT_VeVLDR_b_HCTV_Leak_FltDtct_Value: accessed-variable=VeVLDR_b_HCTV_Leak_FltDtct.Value
              OUT_VeVLDR_b_EXV_PressElctrFlt_FltDtct_Value: accessed-variable=VeVLDR_b_EXV_PressElctrFlt_FltDtct.Value
              OUT_VeVLDR_b_EXV_TempElctrFlt_FltDtct_Value: accessed-variable=VeVLDR_b_EXV_TempElctrFlt_FltDtct.Value
              OUT_VeVLDR_b_EXV_PerfDiag_FltDtct_Value: accessed-variable=VeVLDR_b_EXV_PerfDiag_FltDtct.Value
              OUT_VeVLDR_b_EXV_PressSens_FltDtct_Value: accessed-variable=VeVLDR_b_EXV_PressSens_FltDtct.Value
              OUT_VeVLDR_b_EXV_TempSens_FltDtct_Value: accessed-variable=VeVLDR_b_EXV_TempSens_FltDtct.Value
              OUT_VeVLDR_b_IUMPR_EXV_PerfDiag_Value: accessed-variable=VeVLDR_b_IUMPR_EXV_PerfDiag.Value
              OUT_VeVLDR_b_IUMPR_EXV_TempSensRat_Value: accessed-variable=VeVLDR_b_IUMPR_EXV_TempSensRat.Value
              OUT_VeVLDR_b_IUMPR_EXV_PressSensRat_Value: accessed-variable=VeVLDR_b_IUMPR_EXV_PressSensRat.Value
              OUT_VeVLDR_b_IUMPR_LTSOV_StuckOff_Value: accessed-variable=VeVLDR_b_IUMPR_LTSOV_StuckOff.Value
              OUT_VeVLDR_b_IUMPR_LTSOV_StuckOn_Value: accessed-variable=VeVLDR_b_IUMPR_LTSOV_StuckOn.Value
              OUT_VeVLDR_b_IUMPR_EXV_perf_MinCmdThrshld_Met_Value: accessed-variable=VeVLDR_b_IUMPR_EXV_perf_MinCmdThrshld_Met.Value
              OUT_VeVLDR_b_IUMPR_EXV_presSens_MinCmdThrshld_Met_Value: accessed-variable=VeVLDR_b_IUMPR_EXV_presSens_MinCmdThrshld_Met.Value
              OUT_VeVLDR_b_IUMPR_LTSOV_StkOff_MinCmdThrshld_Met_Value: accessed-variable=VeVLDR_b_IUMPR_LTSOV_StkOff_MinCmdThrshld_Met.Value
              OUT_VeVLDR_b_IUMPR_LTSOV_StkOn_MinCmdThrshld_Met_Value: accessed-variable=VeVLDR_b_IUMPR_LTSOV_StkOn_MinCmdThrshld_Met.Value
              OUT_VeVLDR_b_EXV_PressShrtHigh_Value: accessed-variable=VeVLDR_b_EXV_PressShrtHigh.Value
              OUT_VeVLDR_b_EEXV_PressElctrFlt_FltDtct_Value: accessed-variable=VeVLDR_b_EEXV_PressElctrFlt_FltDtct.Value
              OUT_VeVLDR_b_EEXV_TempElctrFlt_FltDtct_Value: accessed-variable=VeVLDR_b_EEXV_TempElctrFlt_FltDtct.Value
              OUT_VeVLDR_b_EEXV_PerfDiag_FltDtct_Value: accessed-variable=VeVLDR_b_EEXV_PerfDiag_FltDtct.Value
              OUT_VeVLDR_b_EEXV_PressSens_FltDtct_Value: accessed-variable=VeVLDR_b_EEXV_PressSens_FltDtct.Value
              OUT_VeVLDR_b_EEXV_PressShrtHigh_Value: accessed-variable=VeVLDR_b_EEXV_PressShrtHigh.Value
              OUT_VeVLDR_b_OEXV_PressElctrFlt_FltDtct_Value: accessed-variable=VeVLDR_b_OEXV_PressElctrFlt_FltDtct.Value
              OUT_VeVLDR_b_OEXV_TempElctrFlt_FltDtct_Value: accessed-variable=VeVLDR_b_OEXV_TempElctrFlt_FltDtct.Value
              OUT_VeVLDR_b_OEXV_PerfDiag_FltDtct_Value: accessed-variable=VeVLDR_b_OEXV_PerfDiag_FltDtct.Value
              OUT_VeVLDR_b_OEXV_PressSens_FltDtct_Value: accessed-variable=VeVLDR_b_OEXV_PressSens_FltDtct.Value
              OUT_VeVLDR_b_OEXV_PressShrtHigh_Value: accessed-variable=VeVLDR_b_OEXV_PressShrtHigh.Value
              OUT_VeVLDR_b_IUMPR_EEXV_PerfDiag_Value: accessed-variable=VeVLDR_b_IUMPR_EEXV_PerfDiag.Value
              OUT_VeVLDR_b_IUMPR_EEXV_PressSensRat_Value: accessed-variable=VeVLDR_b_IUMPR_EEXV_PressSensRat.Value
              OUT_VeVLDR_b_IUMPR_EEXV_perf_MinCmdThrshld_Met_Value: accessed-variable=VeVLDR_b_IUMPR_EEXV_perf_MinCmdThrshld_Met.Value
              OUT_VeVLDR_b_IUMPR_EEXV_presSens_MinCmdThrshld_Met_Value: accessed-variable=VeVLDR_b_IUMPR_EEXV_presSens_MinCmdThrshld_Met.Value
              OUT_VeVLDR_b_IUMPR_OEXV_PerfDiag_Value: accessed-variable=VeVLDR_b_IUMPR_OEXV_PerfDiag.Value
              OUT_VeVLDR_b_IUMPR_OEXV_PressSensRat_Value: accessed-variable=VeVLDR_b_IUMPR_OEXV_PressSensRat.Value
              OUT_VeVLDR_b_IUMPR_OEXV_perf_MinCmdThrshld_Met_Value: accessed-variable=VeVLDR_b_IUMPR_OEXV_perf_MinCmdThrshld_Met.Value
              OUT_VeVLDR_b_IUMPR_OEXV_presSens_MinCmdThrshld_Met_Value: accessed-variable=VeVLDR_b_IUMPR_OEXV_presSens_MinCmdThrshld_Met.Value
              OUT_VeVLDR_e_FaultSts_HB_PSC_CtrlValACktPerf_Value: accessed-variable=VeVLDR_e_FaultSts_HB_PSC_CtrlValACktPerf.Value
              OUT_VeVLDR_e_FaultSts_AC_RefrigExpVlvAct_C_CntrlCktPerf_Value: accessed-variable=VeVLDR_e_FaultSts_AC_RefrigExpVlvAct_C_CntrlCktPerf.Value
              OUT_VeVLDR_e_FaultSts_AC_RefrigPresSnsrCCkt_Value: accessed-variable=VeVLDR_e_FaultSts_AC_RefrigPresSnsrCCkt.Value
              OUT_VeVLDR_e_FaultSts_AC_RefrigPresSnsrCCktPerf_Value: accessed-variable=VeVLDR_e_FaultSts_AC_RefrigPresSnsrCCktPerf.Value
              OUT_VeVLDR_e_FaultSts_AC_RefrigTempSnsrCCkt_Value: accessed-variable=VeVLDR_e_FaultSts_AC_RefrigTempSnsrCCkt.Value
              OUT_VeVLDR_e_FaultSts_CoolantVlvA_StkOpn_Value: accessed-variable=VeVLDR_e_FaultSts_CoolantVlvA_StkOpn.Value
              OUT_VeVLDR_e_FaultSts_CoolantVlvA_Perf_Value: accessed-variable=VeVLDR_e_FaultSts_CoolantVlvA_Perf.Value
              OUT_VeVLDR_e_FaultSts_HB_PSC_CtrlValCCktPerf_Value: accessed-variable=VeVLDR_e_FaultSts_HB_PSC_CtrlValCCktPerf.Value
              OUT_VeVLDR_e_FaultSts_CoolantVlvB_StkClsd_Value: accessed-variable=VeVLDR_e_FaultSts_CoolantVlvB_StkClsd.Value
              OUT_VeVLDR_e_FaultSts_CoolantVlvB_StkOpn_Value: accessed-variable=VeVLDR_e_FaultSts_CoolantVlvB_StkOpn.Value
              OUT_VeVLDR_e_FaultSts_HB_PSC_CtrlValBCktPerf_Value: accessed-variable=VeVLDR_e_FaultSts_HB_PSC_CtrlValBCktPerf.Value
              OUT_VeVLDR_e_FaultSts_HybEvBatPacCoolCtrlVlvBPerfStkOff_Value: accessed-variable=VeVLDR_e_FaultSts_HybEvBatPacCoolCtrlVlvBPerfStkOff.Value
              OUT_VeVLDR_e_FaultSts_HybEvBatPacCoolCtrlVlvBStkOn_Value: accessed-variable=VeVLDR_e_FaultSts_HybEvBatPacCoolCtrlVlvBStkOn.Value
              OUT_VeVLDR_e_FaultSts_AC_RefrigExpVlvActD_CntrlCktPerf_Value: accessed-variable=VeVLDR_e_FaultSts_AC_RefrigExpVlvActD_CntrlCktPerf.Value
              OUT_VeVLDR_e_FaultSts_AC_RefrigPresSnsrDCkt_Value: accessed-variable=VeVLDR_e_FaultSts_AC_RefrigPresSnsrDCkt.Value
              OUT_VeVLDR_e_FaultSts_AC_RefrigPresSnsrDCktPerf_Value: accessed-variable=VeVLDR_e_FaultSts_AC_RefrigPresSnsrDCktPerf.Value
              OUT_VeVLDR_e_FaultSts_AC_RefrigTempSnsrDCkt_Value: accessed-variable=VeVLDR_e_FaultSts_AC_RefrigTempSnsrDCkt.Value
              OUT_VeVLDR_e_FaultSts_AC_RefrigExpVlvActCtrCktPerf_Value: accessed-variable=VeVLDR_e_FaultSts_AC_RefrigExpVlvActCtrCktPerf.Value
              OUT_VeVLDR_e_FaultSts_AC_RefrigTempSnsrBCkt_Value: accessed-variable=VeVLDR_e_FaultSts_AC_RefrigTempSnsrBCkt.Value
              OUT_VeVLDR_e_FaultSts_AC_RefrigTempSnsrBPerf_Value: accessed-variable=VeVLDR_e_FaultSts_AC_RefrigTempSnsrBPerf.Value
              OUT_VeVLDR_e_FaultSts_AC_RefrigTempSnsrACkt_Value: accessed-variable=VeVLDR_e_FaultSts_AC_RefrigTempSnsrACkt.Value
              OUT_VeVLDR_e_FaultSts_AC_RefrigTempSnsrAPerf_Value: accessed-variable=VeVLDR_e_FaultSts_AC_RefrigTempSnsrAPerf.Value
              OUT_VeVLDR_e_FaultSts_EngCoolbypsVlvDPerf_Value: accessed-variable=VeVLDR_e_FaultSts_EngCoolbypsVlvDPerf.Value
              OUT_VeVLDR_e_FaultSts_HybPropSysCoolCntrlVal_E_Perf_Value: accessed-variable=VeVLDR_e_FaultSts_HybPropSysCoolCntrlVal_E_Perf.Value
        VLDR_PwrOn
          data-receive-point-by-arguments:
            24 x access:
              IN_NeVLDR_Cnt_BHV_PerfDiag_MFOP_Rx_NeVLDR_Cnt_BHV_PerfDiag_MFOP: accessed-variable=NeVLDR_Cnt_BHV_PerfDiag_MFOP_Rx.NeVLDR_Cnt_BHV_PerfDiag_MFOP
              IN_NeVLDR_Cnt_CPV2_PerfDiag_MFOP_Rx_NeVLDR_Cnt_CPV2_PerfDiag_MFOP: accessed-variable=NeVLDR_Cnt_CPV2_PerfDiag_MFOP_Rx.NeVLDR_Cnt_CPV2_PerfDiag_MFOP
              IN_NeVLDR_Cnt_CPV_PerfDiag_MFOP_Rx_NeVLDR_Cnt_CPV_PerfDiag_MFOP: accessed-variable=NeVLDR_Cnt_CPV_PerfDiag_MFOP_Rx.NeVLDR_Cnt_CPV_PerfDiag_MFOP
              IN_NeVLDR_Cnt_CabVlvOpeng_Err_MFOP_Rx_NeVLDR_Cnt_CabVlvOpeng_Err_MFOP: accessed-variable=NeVLDR_Cnt_CabVlvOpeng_Err_MFOP_Rx.NeVLDR_Cnt_CabVlvOpeng_Err_MFOP
              IN_NeVLDR_Cnt_EEXV_PerfDiag_MFOP_Rx_NeVLDR_Cnt_EEXV_PerfDiag_MFOP: accessed-variable=NeVLDR_Cnt_EEXV_PerfDiag_MFOP_Rx.NeVLDR_Cnt_EEXV_PerfDiag_MFOP
              IN_NeVLDR_Cnt_EEXV_PressElctrFlt_MFOP_Rx_NeVLDR_Cnt_EEXV_PressElctrFlt_MFOP: accessed-variable=NeVLDR_Cnt_EEXV_PressElctrFlt_MFOP_Rx.NeVLDR_Cnt_EEXV_PressElctrFlt_MFOP
              IN_NeVLDR_Cnt_EEXV_PressSens_MFOP_Rx_NeVLDR_Cnt_EEXV_PressSens_MFOP: accessed-variable=NeVLDR_Cnt_EEXV_PressSens_MFOP_Rx.NeVLDR_Cnt_EEXV_PressSens_MFOP
              IN_NeVLDR_Cnt_EEXV_TempElctrFlt_MFOP_Rx_NeVLDR_Cnt_EEXV_TempElctrFlt_MFOP: accessed-variable=NeVLDR_Cnt_EEXV_TempElctrFlt_MFOP_Rx.NeVLDR_Cnt_EEXV_TempElctrFlt_MFOP
              IN_NeVLDR_Cnt_EXV_PerfDiag_MFOP_Rx_NeVLDR_Cnt_EXV_PerfDiag_MFOP: accessed-variable=NeVLDR_Cnt_EXV_PerfDiag_MFOP_Rx.NeVLDR_Cnt_EXV_PerfDiag_MFOP
              IN_NeVLDR_Cnt_EXV_PressElctrFlt_MFOP_Rx_NeVLDR_Cnt_EXV_PressElctrFlt_MFOP: accessed-variable=NeVLDR_Cnt_EXV_PressElctrFlt_MFOP_Rx.NeVLDR_Cnt_EXV_PressElctrFlt_MFOP
              IN_NeVLDR_Cnt_EXV_PressSens_MFOP_Rx_NeVLDR_Cnt_EXV_PressSens_MFOP: accessed-variable=NeVLDR_Cnt_EXV_PressSens_MFOP_Rx.NeVLDR_Cnt_EXV_PressSens_MFOP
              IN_NeVLDR_Cnt_EXV_TempElctrFlt_MFOP_Rx_NeVLDR_Cnt_EXV_TempElctrFlt_MFOP: accessed-variable=NeVLDR_Cnt_EXV_TempElctrFlt_MFOP_Rx.NeVLDR_Cnt_EXV_TempElctrFlt_MFOP
              IN_NeVLDR_Cnt_EXV_TempSens_MFOP_Rx_NeVLDR_Cnt_EXV_TempSens_MFOP: accessed-variable=NeVLDR_Cnt_EXV_TempSens_MFOP_Rx.NeVLDR_Cnt_EXV_TempSens_MFOP
              IN_NeVLDR_Cnt_HCTV_Leak_MFOP_Rx_NeVLDR_Cnt_HCTV_Leak_MFOP: accessed-variable=NeVLDR_Cnt_HCTV_Leak_MFOP_Rx.NeVLDR_Cnt_HCTV_Leak_MFOP
              IN_NeVLDR_Cnt_HTL_PerfDiag_MFOP_Rx_NeVLDR_Cnt_HTL_PerfDiag_MFOP: accessed-variable=NeVLDR_Cnt_HTL_PerfDiag_MFOP_Rx.NeVLDR_Cnt_HTL_PerfDiag_MFOP
              IN_NeVLDR_Cnt_HTSoV_StkCls_MFOP_Rx_NeVLDR_Cnt_HTSoV_StkCls_MFOP: accessed-variable=NeVLDR_Cnt_HTSoV_StkCls_MFOP_Rx.NeVLDR_Cnt_HTSoV_StkCls_MFOP
              IN_NeVLDR_Cnt_HTSoV_StkOpn_MFOP_Rx_NeVLDR_Cnt_HTSoV_StkOpn_MFOP: accessed-variable=NeVLDR_Cnt_HTSoV_StkOpn_MFOP_Rx.NeVLDR_Cnt_HTSoV_StkOpn_MFOP
              IN_NeVLDR_Cnt_LTR_PerfDiag_MFOP_Rx_NeVLDR_Cnt_LTR_PerfDiag_MFOP: accessed-variable=NeVLDR_Cnt_LTR_PerfDiag_MFOP_Rx.NeVLDR_Cnt_LTR_PerfDiag_MFOP
              IN_NeVLDR_Cnt_LTSOV_StkOff_MFOP_Rx_NeVLDR_Cnt_LTSOV_StkOff_MFOP: accessed-variable=NeVLDR_Cnt_LTSOV_StkOff_MFOP_Rx.NeVLDR_Cnt_LTSOV_StkOff_MFOP
              IN_NeVLDR_Cnt_LTSOV_StkOn_MFOP_Rx_NeVLDR_Cnt_LTSOV_StkOn_MFOP: accessed-variable=NeVLDR_Cnt_LTSOV_StkOn_MFOP_Rx.NeVLDR_Cnt_LTSOV_StkOn_MFOP
              IN_NeVLDR_Cnt_OEXV_PerfDiag_MFOP_Rx_NeVLDR_Cnt_OEXV_PerfDiag_MFOP: accessed-variable=NeVLDR_Cnt_OEXV_PerfDiag_MFOP_Rx.NeVLDR_Cnt_OEXV_PerfDiag_MFOP
              IN_NeVLDR_Cnt_OEXV_PressElctrFlt_MFOP_Rx_NeVLDR_Cnt_OEXV_PressElctrFlt_MFOP: accessed-variable=NeVLDR_Cnt_OEXV_PressElctrFlt_MFOP_Rx.NeVLDR_Cnt_OEXV_PressElctrFlt_MFOP
              IN_NeVLDR_Cnt_OEXV_PressSens_MFOP_Rx_NeVLDR_Cnt_OEXV_PressSens_MFOP: accessed-variable=NeVLDR_Cnt_OEXV_PressSens_MFOP_Rx.NeVLDR_Cnt_OEXV_PressSens_MFOP
              IN_NeVLDR_Cnt_OEXV_TempElctrFlt_MFOP_Rx_NeVLDR_Cnt_OEXV_TempElctrFlt_MFOP: accessed-variable=NeVLDR_Cnt_OEXV_TempElctrFlt_MFOP_Rx.NeVLDR_Cnt_OEXV_TempElctrFlt_MFOP
          data-send-points:
            70 x access:
              OUT_VeVLDR_b_HTCV_Leak_DiagEnbl_Value: accessed-variable=VeVLDR_b_HTCV_Leak_DiagEnbl.Value
              OUT_VeVLDR_b_IUMPR_HTSOV_StkClsd_Value: accessed-variable=VeVLDR_b_IUMPR_HTSOV_StkClsd.Value
              OUT_VeVLDR_b_IUMPR_HTSOV_StkOpn_Value: accessed-variable=VeVLDR_b_IUMPR_HTSOV_StkOpn.Value
              OUT_VeVLDR_b_IUMPR_HTCV_Perf_Value: accessed-variable=VeVLDR_b_IUMPR_HTCV_Perf.Value
              OUT_VeVLDR_b_IUMPR_HTCV_Leak_Value: accessed-variable=VeVLDR_b_IUMPR_HTCV_Leak.Value
              OUT_VeVLDR_b_IUMPR_HTSOV_MinCmdThrshld_Met_Value: accessed-variable=VeVLDR_b_IUMPR_HTSOV_MinCmdThrshld_Met.Value
              OUT_VeVLDR_b_IUMPR_HTCV_MinCmdThrshld_Met_Value: accessed-variable=VeVLDR_b_IUMPR_HTCV_MinCmdThrshld_Met.Value
              OUT_VeVLDR_b_HTSoV_StkCls_XYEnbl_Value: accessed-variable=VeVLDR_b_HTSoV_StkCls_XYEnbl.Value
              OUT_VeVLDR_b_HTSoV_StkOpn_XYEnbl_Value: accessed-variable=VeVLDR_b_HTSoV_StkOpn_XYEnbl.Value
              OUT_VeVLDR_b_HTSoV_StkCls_FltDtct_Value: accessed-variable=VeVLDR_b_HTSoV_StkCls_FltDtct.Value
              OUT_VeVLDR_b_HTSoV_StkOpn_FltDtct_Value: accessed-variable=VeVLDR_b_HTSoV_StkOpn_FltDtct.Value
              OUT_VeVLDR_b_HTCV_Stck_FltDtct_Value: accessed-variable=VeVLDR_b_HTCV_Stck_FltDtct.Value
              OUT_VeVLDR_b_HCTV_Leak_FltDtct_Value: accessed-variable=VeVLDR_b_HCTV_Leak_FltDtct.Value
              OUT_VeVLDR_b_EXV_PressElctrFlt_FltDtct_Value: accessed-variable=VeVLDR_b_EXV_PressElctrFlt_FltDtct.Value
              OUT_VeVLDR_b_EXV_TempElctrFlt_FltDtct_Value: accessed-variable=VeVLDR_b_EXV_TempElctrFlt_FltDtct.Value
              OUT_VeVLDR_b_EXV_PerfDiag_FltDtct_Value: accessed-variable=VeVLDR_b_EXV_PerfDiag_FltDtct.Value
              OUT_VeVLDR_b_EXV_PressSens_FltDtct_Value: accessed-variable=VeVLDR_b_EXV_PressSens_FltDtct.Value
              OUT_VeVLDR_b_EXV_TempSens_FltDtct_Value: accessed-variable=VeVLDR_b_EXV_TempSens_FltDtct.Value
              OUT_VeVLDR_b_IUMPR_EXV_PerfDiag_Value: accessed-variable=VeVLDR_b_IUMPR_EXV_PerfDiag.Value
              OUT_VeVLDR_b_IUMPR_EXV_TempSensRat_Value: accessed-variable=VeVLDR_b_IUMPR_EXV_TempSensRat.Value
              OUT_VeVLDR_b_IUMPR_EXV_PressSensRat_Value: accessed-variable=VeVLDR_b_IUMPR_EXV_PressSensRat.Value
              OUT_VeVLDR_b_IUMPR_LTSOV_StuckOff_Value: accessed-variable=VeVLDR_b_IUMPR_LTSOV_StuckOff.Value
              OUT_VeVLDR_b_IUMPR_LTSOV_StuckOn_Value: accessed-variable=VeVLDR_b_IUMPR_LTSOV_StuckOn.Value
              OUT_VeVLDR_b_IUMPR_EXV_perf_MinCmdThrshld_Met_Value: accessed-variable=VeVLDR_b_IUMPR_EXV_perf_MinCmdThrshld_Met.Value
              OUT_VeVLDR_b_IUMPR_EXV_presSens_MinCmdThrshld_Met_Value: accessed-variable=VeVLDR_b_IUMPR_EXV_presSens_MinCmdThrshld_Met.Value
              OUT_VeVLDR_b_IUMPR_LTSOV_StkOff_MinCmdThrshld_Met_Value: accessed-variable=VeVLDR_b_IUMPR_LTSOV_StkOff_MinCmdThrshld_Met.Value
              OUT_VeVLDR_b_IUMPR_LTSOV_StkOn_MinCmdThrshld_Met_Value: accessed-variable=VeVLDR_b_IUMPR_LTSOV_StkOn_MinCmdThrshld_Met.Value
              OUT_VeVLDR_b_EXV_PressShrtHigh_Value: accessed-variable=VeVLDR_b_EXV_PressShrtHigh.Value
              OUT_VeVLDR_b_EEXV_PressElctrFlt_FltDtct_Value: accessed-variable=VeVLDR_b_EEXV_PressElctrFlt_FltDtct.Value
              OUT_VeVLDR_b_EEXV_TempElctrFlt_FltDtct_Value: accessed-variable=VeVLDR_b_EEXV_TempElctrFlt_FltDtct.Value
              OUT_VeVLDR_b_EEXV_PerfDiag_FltDtct_Value: accessed-variable=VeVLDR_b_EEXV_PerfDiag_FltDtct.Value
              OUT_VeVLDR_b_EEXV_PressSens_FltDtct_Value: accessed-variable=VeVLDR_b_EEXV_PressSens_FltDtct.Value
              OUT_VeVLDR_b_EEXV_PressShrtHigh_Value: accessed-variable=VeVLDR_b_EEXV_PressShrtHigh.Value
              OUT_VeVLDR_b_OEXV_PressElctrFlt_FltDtct_Value: accessed-variable=VeVLDR_b_OEXV_PressElctrFlt_FltDtct.Value
              OUT_VeVLDR_b_OEXV_TempElctrFlt_FltDtct_Value: accessed-variable=VeVLDR_b_OEXV_TempElctrFlt_FltDtct.Value
              OUT_VeVLDR_b_OEXV_PerfDiag_FltDtct_Value: accessed-variable=VeVLDR_b_OEXV_PerfDiag_FltDtct.Value
              OUT_VeVLDR_b_OEXV_PressSens_FltDtct_Value: accessed-variable=VeVLDR_b_OEXV_PressSens_FltDtct.Value
              OUT_VeVLDR_b_OEXV_PressShrtHigh_Value: accessed-variable=VeVLDR_b_OEXV_PressShrtHigh.Value
              OUT_VeVLDR_b_IUMPR_EEXV_PerfDiag_Value: accessed-variable=VeVLDR_b_IUMPR_EEXV_PerfDiag.Value
              OUT_VeVLDR_b_IUMPR_EEXV_PressSensRat_Value: accessed-variable=VeVLDR_b_IUMPR_EEXV_PressSensRat.Value
              OUT_VeVLDR_b_IUMPR_EEXV_perf_MinCmdThrshld_Met_Value: accessed-variable=VeVLDR_b_IUMPR_EEXV_perf_MinCmdThrshld_Met.Value
              OUT_VeVLDR_b_IUMPR_EEXV_presSens_MinCmdThrshld_Met_Value: accessed-variable=VeVLDR_b_IUMPR_EEXV_presSens_MinCmdThrshld_Met.Value
              OUT_VeVLDR_b_IUMPR_OEXV_PerfDiag_Value: accessed-variable=VeVLDR_b_IUMPR_OEXV_PerfDiag.Value
              OUT_VeVLDR_b_IUMPR_OEXV_PressSensRat_Value: accessed-variable=VeVLDR_b_IUMPR_OEXV_PressSensRat.Value
              OUT_VeVLDR_b_IUMPR_OEXV_perf_MinCmdThrshld_Met_Value: accessed-variable=VeVLDR_b_IUMPR_OEXV_perf_MinCmdThrshld_Met.Value
              OUT_VeVLDR_b_IUMPR_OEXV_presSens_MinCmdThrshld_Met_Value: accessed-variable=VeVLDR_b_IUMPR_OEXV_presSens_MinCmdThrshld_Met.Value
              OUT_VeVLDR_e_FaultSts_HB_PSC_CtrlValACktPerf_Value: accessed-variable=VeVLDR_e_FaultSts_HB_PSC_CtrlValACktPerf.Value
              OUT_VeVLDR_e_FaultSts_AC_RefrigExpVlvAct_C_CntrlCktPerf_Value: accessed-variable=VeVLDR_e_FaultSts_AC_RefrigExpVlvAct_C_CntrlCktPerf.Value
              OUT_VeVLDR_e_FaultSts_AC_RefrigPresSnsrCCkt_Value: accessed-variable=VeVLDR_e_FaultSts_AC_RefrigPresSnsrCCkt.Value
              OUT_VeVLDR_e_FaultSts_AC_RefrigPresSnsrCCktPerf_Value: accessed-variable=VeVLDR_e_FaultSts_AC_RefrigPresSnsrCCktPerf.Value
              OUT_VeVLDR_e_FaultSts_AC_RefrigTempSnsrCCkt_Value: accessed-variable=VeVLDR_e_FaultSts_AC_RefrigTempSnsrCCkt.Value
              OUT_VeVLDR_e_FaultSts_CoolantVlvA_StkOpn_Value: accessed-variable=VeVLDR_e_FaultSts_CoolantVlvA_StkOpn.Value
              OUT_VeVLDR_e_FaultSts_CoolantVlvA_Perf_Value: accessed-variable=VeVLDR_e_FaultSts_CoolantVlvA_Perf.Value
              OUT_VeVLDR_e_FaultSts_HB_PSC_CtrlValCCktPerf_Value: accessed-variable=VeVLDR_e_FaultSts_HB_PSC_CtrlValCCktPerf.Value
              OUT_VeVLDR_e_FaultSts_CoolantVlvB_StkClsd_Value: accessed-variable=VeVLDR_e_FaultSts_CoolantVlvB_StkClsd.Value
              OUT_VeVLDR_e_FaultSts_CoolantVlvB_StkOpn_Value: accessed-variable=VeVLDR_e_FaultSts_CoolantVlvB_StkOpn.Value
              OUT_VeVLDR_e_FaultSts_HB_PSC_CtrlValBCktPerf_Value: accessed-variable=VeVLDR_e_FaultSts_HB_PSC_CtrlValBCktPerf.Value
              OUT_VeVLDR_e_FaultSts_HybEvBatPacCoolCtrlVlvBPerfStkOff_Value: accessed-variable=VeVLDR_e_FaultSts_HybEvBatPacCoolCtrlVlvBPerfStkOff.Value
              OUT_VeVLDR_e_FaultSts_HybEvBatPacCoolCtrlVlvBStkOn_Value: accessed-variable=VeVLDR_e_FaultSts_HybEvBatPacCoolCtrlVlvBStkOn.Value
              OUT_VeVLDR_e_FaultSts_AC_RefrigExpVlvActD_CntrlCktPerf_Value: accessed-variable=VeVLDR_e_FaultSts_AC_RefrigExpVlvActD_CntrlCktPerf.Value
              OUT_VeVLDR_e_FaultSts_AC_RefrigPresSnsrDCkt_Value: accessed-variable=VeVLDR_e_FaultSts_AC_RefrigPresSnsrDCkt.Value
              OUT_VeVLDR_e_FaultSts_AC_RefrigPresSnsrDCktPerf_Value: accessed-variable=VeVLDR_e_FaultSts_AC_RefrigPresSnsrDCktPerf.Value
              OUT_VeVLDR_e_FaultSts_AC_RefrigTempSnsrDCkt_Value: accessed-variable=VeVLDR_e_FaultSts_AC_RefrigTempSnsrDCkt.Value
              OUT_VeVLDR_e_FaultSts_AC_RefrigExpVlvActCtrCktPerf_Value: accessed-variable=VeVLDR_e_FaultSts_AC_RefrigExpVlvActCtrCktPerf.Value
              OUT_VeVLDR_e_FaultSts_AC_RefrigTempSnsrBCkt_Value: accessed-variable=VeVLDR_e_FaultSts_AC_RefrigTempSnsrBCkt.Value
              OUT_VeVLDR_e_FaultSts_AC_RefrigTempSnsrBPerf_Value: accessed-variable=VeVLDR_e_FaultSts_AC_RefrigTempSnsrBPerf.Value
              OUT_VeVLDR_e_FaultSts_AC_RefrigTempSnsrACkt_Value: accessed-variable=VeVLDR_e_FaultSts_AC_RefrigTempSnsrACkt.Value
              OUT_VeVLDR_e_FaultSts_AC_RefrigTempSnsrAPerf_Value: accessed-variable=VeVLDR_e_FaultSts_AC_RefrigTempSnsrAPerf.Value
              OUT_VeVLDR_e_FaultSts_EngCoolbypsVlvDPerf_Value: accessed-variable=VeVLDR_e_FaultSts_EngCoolbypsVlvDPerf.Value
              OUT_VeVLDR_e_FaultSts_HybPropSysCoolCntrlVal_E_Perf_Value: accessed-variable=VeVLDR_e_FaultSts_HybPropSysCoolCntrlVal_E_Perf.Value
        VLDR_PwrOff
          data-send-points:
            24 x access:
              OUT_NeVLDR_Cnt_CPV_PerfDiag_MFOP_NeVLDR_Cnt_CPV_PerfDiag_MFOP: accessed-variable=NeVLDR_Cnt_CPV_PerfDiag_MFOP.NeVLDR_Cnt_CPV_PerfDiag_MFOP
              OUT_NeVLDR_Cnt_CabVlvOpeng_Err_MFOP_NeVLDR_Cnt_CabVlvOpeng_Err_MFOP: accessed-variable=NeVLDR_Cnt_CabVlvOpeng_Err_MFOP.NeVLDR_Cnt_CabVlvOpeng_Err_MFOP
              OUT_NeVLDR_Cnt_EEXV_PerfDiag_MFOP_NeVLDR_Cnt_EEXV_PerfDiag_MFOP: accessed-variable=NeVLDR_Cnt_EEXV_PerfDiag_MFOP.NeVLDR_Cnt_EEXV_PerfDiag_MFOP
              OUT_NeVLDR_Cnt_EEXV_PressElctrFlt_MFOP_NeVLDR_Cnt_EEXV_PressElctrFlt_MFOP: accessed-variable=NeVLDR_Cnt_EEXV_PressElctrFlt_MFOP.NeVLDR_Cnt_EEXV_PressElctrFlt_MFOP
              OUT_NeVLDR_Cnt_EEXV_PressSens_MFOP_NeVLDR_Cnt_EEXV_PressSens_MFOP: accessed-variable=NeVLDR_Cnt_EEXV_PressSens_MFOP.NeVLDR_Cnt_EEXV_PressSens_MFOP
              OUT_NeVLDR_Cnt_EEXV_TempElctrFlt_MFOP_NeVLDR_Cnt_EEXV_TempElctrFlt_MFOP: accessed-variable=NeVLDR_Cnt_EEXV_TempElctrFlt_MFOP.NeVLDR_Cnt_EEXV_TempElctrFlt_MFOP
              OUT_NeVLDR_Cnt_EXV_PerfDiag_MFOP_NeVLDR_Cnt_EXV_PerfDiag_MFOP: accessed-variable=NeVLDR_Cnt_EXV_PerfDiag_MFOP.NeVLDR_Cnt_EXV_PerfDiag_MFOP
              OUT_NeVLDR_Cnt_EXV_PressElctrFlt_MFOP_NeVLDR_Cnt_EXV_PressElctrFlt_MFOP: accessed-variable=NeVLDR_Cnt_EXV_PressElctrFlt_MFOP.NeVLDR_Cnt_EXV_PressElctrFlt_MFOP
              OUT_NeVLDR_Cnt_EXV_PressSens_MFOP_NeVLDR_Cnt_EXV_PressSens_MFOP: accessed-variable=NeVLDR_Cnt_EXV_PressSens_MFOP.NeVLDR_Cnt_EXV_PressSens_MFOP
              OUT_NeVLDR_Cnt_EXV_TempElctrFlt_MFOP_NeVLDR_Cnt_EXV_TempElctrFlt_MFOP: accessed-variable=NeVLDR_Cnt_EXV_TempElctrFlt_MFOP.NeVLDR_Cnt_EXV_TempElctrFlt_MFOP
              OUT_NeVLDR_Cnt_EXV_TempSens_MFOP_NeVLDR_Cnt_EXV_TempSens_MFOP: accessed-variable=NeVLDR_Cnt_EXV_TempSens_MFOP.NeVLDR_Cnt_EXV_TempSens_MFOP
              OUT_NeVLDR_Cnt_HCTV_Leak_MFOP_NeVLDR_Cnt_HCTV_Leak_MFOP: accessed-variable=NeVLDR_Cnt_HCTV_Leak_MFOP.NeVLDR_Cnt_HCTV_Leak_MFOP
              OUT_NeVLDR_Cnt_HTL_PerfDiag_MFOP_NeVLDR_Cnt_HTL_PerfDiag_MFOP: accessed-variable=NeVLDR_Cnt_HTL_PerfDiag_MFOP.NeVLDR_Cnt_HTL_PerfDiag_MFOP
              OUT_NeVLDR_Cnt_HTSoV_StkCls_MFOP_NeVLDR_Cnt_HTSoV_StkCls_MFOP: accessed-variable=NeVLDR_Cnt_HTSoV_StkCls_MFOP.NeVLDR_Cnt_HTSoV_StkCls_MFOP
              OUT_NeVLDR_Cnt_HTSoV_StkOpn_MFOP_NeVLDR_Cnt_HTSoV_StkOpn_MFOP: accessed-variable=NeVLDR_Cnt_HTSoV_StkOpn_MFOP.NeVLDR_Cnt_HTSoV_StkOpn_MFOP
              OUT_NeVLDR_Cnt_LTR_PerfDiag_MFOP_NeVLDR_Cnt_LTR_PerfDiag_MFOP: accessed-variable=NeVLDR_Cnt_LTR_PerfDiag_MFOP.NeVLDR_Cnt_LTR_PerfDiag_MFOP
              OUT_NeVLDR_Cnt_LTSOV_StkOff_MFOP_NeVLDR_Cnt_LTSOV_StkOff_MFOP: accessed-variable=NeVLDR_Cnt_LTSOV_StkOff_MFOP.NeVLDR_Cnt_LTSOV_StkOff_MFOP
              OUT_NeVLDR_Cnt_LTSOV_StkOn_MFOP_NeVLDR_Cnt_LTSOV_StkOn_MFOP: accessed-variable=NeVLDR_Cnt_LTSOV_StkOn_MFOP.NeVLDR_Cnt_LTSOV_StkOn_MFOP
              OUT_NeVLDR_Cnt_OEXV_PerfDiag_MFOP_NeVLDR_Cnt_OEXV_PerfDiag_MFOP: accessed-variable=NeVLDR_Cnt_OEXV_PerfDiag_MFOP.NeVLDR_Cnt_OEXV_PerfDiag_MFOP
              OUT_NeVLDR_Cnt_OEXV_PressElctrFlt_MFOP_NeVLDR_Cnt_OEXV_PressElctrFlt_MFOP: accessed-variable=NeVLDR_Cnt_OEXV_PressElctrFlt_MFOP.NeVLDR_Cnt_OEXV_PressElctrFlt_MFOP
              OUT_NeVLDR_Cnt_OEXV_PressSens_MFOP_NeVLDR_Cnt_OEXV_PressSens_MFOP: accessed-variable=NeVLDR_Cnt_OEXV_PressSens_MFOP.NeVLDR_Cnt_OEXV_PressSens_MFOP
              OUT_NeVLDR_Cnt_OEXV_TempElctrFlt_MFOP_NeVLDR_Cnt_OEXV_TempElctrFlt_MFOP: accessed-variable=NeVLDR_Cnt_OEXV_TempElctrFlt_MFOP.NeVLDR_Cnt_OEXV_TempElctrFlt_MFOP
              OUT_NeVLDR_Cnt_CPV2_PerfDiag_MFOP_NeVLDR_Cnt_CPV2_PerfDiag_MFOP: accessed-variable=NeVLDR_Cnt_CPV2_PerfDiag_MFOP.NeVLDR_Cnt_CPV2_PerfDiag_MFOP
              OUT_NeVLDR_Cnt_BHV_PerfDiag_MFOP_NeVLDR_Cnt_BHV_PerfDiag_MFOP: accessed-variable=NeVLDR_Cnt_BHV_PerfDiag_MFOP.NeVLDR_Cnt_BHV_PerfDiag_MFOP
      14 x variation point proxy, all with category=CONDITION:
        Variant_VLDR_1: condition-access=1
        Variant_VLDR_10: condition-access=1
        Variant_VLDR_11: condition-access=1
        Variant_VLDR_12: condition-access=0
        Variant_VLDR_13: condition-access=0
        Variant_VLDR_14: condition-access=1
        Variant_VLDR_15: condition-access=1
        Variant_VLDR_2: condition-access=0
        Variant_VLDR_3: condition-access=0
        Variant_VLDR_4: condition-access=1
        Variant_VLDR_5: condition-access=0
        Variant_VLDR_{6..8}: condition-access=1
